VERSION "2027-draft-2026-10-23"

NS_ :

BS_:

BU_: BPS DEI External LVC MIKA MPPTInterface PDU Pedals VCU
VAL_TABLE_ EnableDisable 1 "Enabled" 0 "Disabled" ;
VAL_TABLE_ OnOff 1 "On" 0 "Off" ;
VAL_TABLE_ FaultState 1 "Fault" 0 "OK" ;
VAL_TABLE_ WarningState 1 "Warning" 0 "NoWarning" ;
VAL_TABLE_ DeviceStatus 2 "Waiting" 1 "Fault" 0 "OK" ;
VAL_TABLE_ Permission 1 "Allowed" 0 "NotAllowed" ;
VAL_TABLE_ Connection 1 "Connected" 0 "Disconnected" ;
VAL_TABLE_ BalancingMode 2 "Manual" 1 "Automatic" 0 "Off" ;
VAL_TABLE_ BalancingState 4 "BlockedOrFault" 3 "Complete" 2 "Paused" 1 "Balancing" 0 "Off" ;
VAL_TABLE_ BalancingBlockReason 7 "Other" 6 "BPSFault" 5 "Communication" 4 "VehicleState" 3 "CellVoltage" 2 "ChipTemperature" 1 "CellTemperature" 0 "None" ;
VAL_TABLE_ ServerConnection 1 "Connected" 0 "Disconnected/Retrying" ;
VAL_TABLE_ Pressed 1 "Pressed" 0 "NotPressed" ;
VAL_TABLE_ Validity 1 "Valid" 0 "Invalid" ;
VAL_TABLE_ Watchdog 1 "TimedOut" 0 "Alive" ;
VAL_TABLE_ NormalAdvanced 1 "Advanced" 0 "Normal" ;
VAL_TABLE_ MotorCommandSource 1 "External" 0 "VCU" ;
VAL_TABLE_ Gear 3 "Invalid" 2 "Reverse" 1 "Forward" 0 "Neutral" ;
VAL_TABLE_ BPSFaultSummary 5 "SMBFault" 4 "PrechargeFault" 3 "ContactorRelayFault" 2 "EmergencyStop" 1 "SetpointFault" 0 "OK" ;
VAL_TABLE_ VCUState 7 "VehicleNotReady" 6 "Disabled" 5 "CruiseControl" 4 "Regen" 3 "ReverseDrive" 2 "NeutralDrive" 1 "ForwardDrive" 0 "Init" ;
VAL_TABLE_ ChargeState 2 "Charging" 1 "Standby" 0 "Disabled" ;
VAL_TABLE_ EVSEState 5 "F_EVSEFault" 4 "E_Fault" 3 "D_VentilationRequired" 2 "C_ChargingReady" 1 "B_Connected" 0 "A_Disconnected" ;
VAL_TABLE_ GPSAntennaState 3 "Unknown" 2 "ShortCircuit" 1 "OpenCircuit" 0 "OK" ;
VAL_TABLE_ GPSFix 2 "Fix3D" 1 "Fix2D" 0 "NoFix" ;
VAL_TABLE_ CellularTechnology 4 "Other" 3 "NB_IoT" 2 "LTE_M" 1 "LTE" 0 "None" ;
VAL_TABLE_ TPEEControlMode 2 "ConstantInputVoltage" 1 "PerturbAndObserve" 0 "Disabled" ;
VAL_TABLE_ TPEEOperatingMode 7 "Fault" 6 "MinimumInputVoltage" 5 "TemperatureDerating" 4 "ConstantOutputCurrent" 3 "ConstantOutputVoltage" 2 "MinimumInputCurrent" 1 "ConstantInputCurrent" 0 "ConstantInputVoltage" ;
VAL_TABLE_ TPEEFault 8 "Fault" 7 "PhaseOverCurrent" 6 "InputUnderCurrent" 5 "InputOverCurrent" 4 "OutputOverCurrent" 3 "OutputOverVoltage" 2 "InputOverVoltage" 1 "ConfigurationError" 0 "OK" ;
VAL_TABLE_ LWSCalibration 1 "Calibrated" 0 "NotCalibrated" ;
VAL_TABLE_ LWSTrim 1 "Trimmed" 0 "NotTrimmed" ;
VAL_TABLE_ LWSCommand 5 "ResetCalibration" 3 "SetAngleZero" ;
VAL_TABLE_ ElconControl 1 "Disable" 0 "Charge" ;
VAL_TABLE_ ElconMuxPage 5 "Page5" 4 "Page4" 3 "Page3" 2 "Page2" 1 "Page1" ;

BO_ 81 BPSCommand: 12 External
 SG_ Mode : 0|1@1+ (1,0) [0.0|1.0] "" Vector__XXX
 SG_ MPPTChargeScheme : 1|1@1+ (1,0) [0.0|1.0] "" Vector__XXX
 SG_ VoltageOverrideMask : 2|32@1+ (1,0) [0.0|4294967295.0] "" Vector__XXX
 SG_ TemperatureOverrideMask : 34|32@1+ (1,0) [0.0|4294967295.0] "" Vector__XXX
 SG_ CurrentOverride : 66|1@1+ (1,0) [0.0|1.0] "" Vector__XXX

BO_ 82 PDUCommand: 1 External
 SG_ ChannelIndex : 0|4@1+ (1,0) [0|11] "" Vector__XXX
 SG_ Enable : 4|1@1+ (1,0) [0.0|1.0] "" Vector__XXX

BO_ 83 MotorControllerCommand: 1 External
 SG_ CommandSource : 0|1@1+ (1,0) [0.0|1.0] "" Vector__XXX

BO_ 84 SweepMPPTs: 0 External

BO_ 85 BPSBalancingCommand: 5 External
 SG_ BalancingMode : 0|2@1+ (1,0) [0|2] "" Vector__XXX
 SG_ ManualCellMask : 2|32@1+ (1,0) [0|4294967295] "" Vector__XXX

BO_ 96 BPSStatus: 16 BPS
 SG_ Status : 0|2@1+ (1,0) [0.0|3.0] "" Vector__XXX
 SG_ FaultSummary : 2|3@1+ (1,0) [0.0|7.0] "" Vector__XXX
 SG_ FaultOverTemperature : 5|1@1+ (1,0) [0.0|1.0] "" Vector__XXX
 SG_ FaultOverVoltage : 6|1@1+ (1,0) [0.0|1.0] "" Vector__XXX
 SG_ FaultUnderVoltage : 7|1@1+ (1,0) [0.0|1.0] "" Vector__XXX
 SG_ FaultChargeOverCurrent : 8|1@1+ (1,0) [0.0|1.0] "" Vector__XXX
 SG_ FaultDischargeOverCurrent : 9|1@1+ (1,0) [0.0|1.0] "" Vector__XXX
 SG_ FaultHVPositiveContactorMismatch : 10|1@1+ (1,0) [0.0|1.0] "" Vector__XXX
 SG_ FaultMotorContactorMismatch : 11|1@1+ (1,0) [0.0|1.0] "" Vector__XXX
 SG_ FaultHVNegativeContactorMismatch : 12|1@1+ (1,0) [0.0|1.0] "" Vector__XXX
 SG_ FaultMainPrechargeRelayMismatch : 13|1@1+ (1,0) [0.0|1.0] "" Vector__XXX
 SG_ FaultMotorPrechargeRelayMismatch : 14|1@1+ (1,0) [0.0|1.0] "" Vector__XXX
 SG_ FaultDriverEstop : 15|1@1+ (1,0) [0.0|1.0] "" Vector__XXX
 SG_ FaultExternalEstop : 16|1@1+ (1,0) [0.0|1.0] "" Vector__XXX
 SG_ FaultBatteryEstop : 17|1@1+ (1,0) [0.0|1.0] "" Vector__XXX
 SG_ FaultChargerEstop : 18|1@1+ (1,0) [0.0|1.0] "" Vector__XXX
 SG_ FaultMainPrechargeTimeout : 19|1@1+ (1,0) [0.0|1.0] "" Vector__XXX
 SG_ FaultMotorPrechargeTimeout : 20|1@1+ (1,0) [0.0|1.0] "" Vector__XXX
 SG_ FaultMainVoltage : 21|1@1+ (1,0) [0.0|1.0] "" Vector__XXX
 SG_ FaultMotorVoltage : 22|1@1+ (1,0) [0.0|1.0] "" Vector__XXX
 SG_ FaultMainPrechargeVoltage : 23|1@1+ (1,0) [0.0|1.0] "" Vector__XXX
 SG_ FaultMotorPrechargeVoltage : 24|1@1+ (1,0) [0.0|1.0] "" Vector__XXX
 SG_ WarningSMBCommunication : 25|1@1+ (1,0) [0.0|1.0] "" Vector__XXX
 SG_ WarningUnderVoltage : 26|1@1+ (1,0) [0.0|1.0] "" Vector__XXX
 SG_ WarningOverVoltage : 27|1@1+ (1,0) [0.0|1.0] "" Vector__XXX
 SG_ WarningChargeOverTemperature : 28|1@1+ (1,0) [0.0|1.0] "" Vector__XXX
 SG_ WarningDischargeOverTemperature : 29|1@1+ (1,0) [0.0|1.0] "" Vector__XXX
 SG_ WarningBatteryFan1 : 30|1@1+ (1,0) [0.0|1.0] "" Vector__XXX
 SG_ WarningBatteryFan2 : 31|1@1+ (1,0) [0.0|1.0] "" Vector__XXX
 SG_ WarningBPSFan : 32|1@1+ (1,0) [0.0|1.0] "" Vector__XXX
 SG_ DischargeSafe : 33|1@1+ (1,0) [0.0|1.0] "" Vector__XXX
 SG_ ChargeSafe : 34|1@1+ (1,0) [0.0|1.0] "" Vector__XXX
 SG_ MPPTSetMode : 35|2@1+ (1,0) [0.0|3.0] "" Vector__XXX
 SG_ RegenSafe : 37|1@1+ (1,0) [0.0|1.0] "" Vector__XXX
 SG_ HVPositiveContactor : 38|1@1+ (1,0) [0.0|1.0] "" Vector__XXX
 SG_ MotorContactor : 39|1@1+ (1,0) [0.0|1.0] "" Vector__XXX
 SG_ HVNegativeContactor : 40|1@1+ (1,0) [0.0|1.0] "" Vector__XXX
 SG_ MainPrechargeRelay : 41|1@1+ (1,0) [0.0|1.0] "" Vector__XXX
 SG_ MotorPrechargeRelay : 42|1@1+ (1,0) [0.0|1.0] "" Vector__XXX
 SG_ BalancingActive : 43|1@1+ (1,0) [0.0|1.0] "" Vector__XXX
 SG_ MPPTVoltageLimit : 44|16@1+ (0.05,0) [0|175] "V" Vector__XXX
 SG_ MPPTCurrentLimit : 60|16@1+ (0.01,0) [0|16.38] "A" Vector__XXX
 SG_ BatteryFanTach1 : 76|12@1+ (5,0) [0.0|20475.0] "rpm" Vector__XXX
 SG_ BatteryFanTach2 : 88|12@1+ (5,0) [0.0|20475.0] "rpm" Vector__XXX
 SG_ BPSFanTach : 100|12@1+ (5,0) [0.0|20475.0] "rpm" Vector__XXX

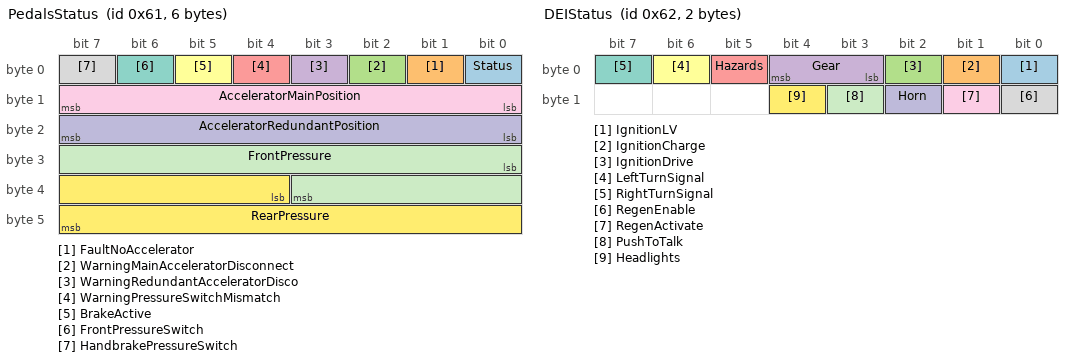
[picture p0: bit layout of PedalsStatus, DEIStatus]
BO_ 97 PedalsStatus: 6 Pedals
 SG_ Status : 0|1@1+ (1,0) [0.0|1.0] "" Vector__XXX
 SG_ FaultNoAccelerator : 1|1@1+ (1,0) [0.0|1.0] "" Vector__XXX
 SG_ WarningMainAcceleratorDisconnect : 2|1@1+ (1,0) [0.0|1.0] "" Vector__XXX
 SG_ WarningRedundantAcceleratorDisco : 3|1@1+ (1,0) [0.0|1.0] "" Vector__XXX
 SG_ WarningPressureSwitchMismatch : 4|1@1+ (1,0) [0.0|1.0] "" Vector__XXX
 SG_ BrakeActive : 5|1@1+ (1,0) [0.0|1.0] "" Vector__XXX
 SG_ FrontPressureSwitch : 6|1@1+ (1,0) [0.0|1.0] "" Vector__XXX
 SG_ HandbrakePressureSwitch : 7|1@1+ (1,0) [0.0|1.0] "" Vector__XXX
 SG_ AcceleratorMainPosition : 8|8@1+ (0.39215686274509803,0) [0|100] "%" Vector__XXX
 SG_ AcceleratorRedundantPosition : 16|8@1+ (0.39215686274509803,0) [0|100] "%" Vector__XXX
 SG_ FrontPressure : 24|12@1+ (1,0) [0|3000] "PSI" Vector__XXX
 SG_ RearPressure : 36|12@1+ (1,0) [0|3000] "PSI" Vector__XXX

BO_ 98 DEIStatus: 2 DEI
 SG_ IgnitionLV : 0|1@1+ (1,0) [0.0|1.0] "" Vector__XXX
 SG_ IgnitionCharge : 1|1@1+ (1,0) [0.0|1.0] "" Vector__XXX
 SG_ IgnitionDrive : 2|1@1+ (1,0) [0.0|1.0] "" Vector__XXX
 SG_ Gear : 3|2@1+ (1,0) [0.0|3.0] "" Vector__XXX
 SG_ Hazards : 5|1@1+ (1,0) [0.0|1.0] "" Vector__XXX
 SG_ LeftTurnSignal : 6|1@1+ (1,0) [0.0|1.0] "" Vector__XXX
 SG_ RightTurnSignal : 7|1@1+ (1,0) [0.0|1.0] "" Vector__XXX
 SG_ RegenEnable : 8|1@1+ (1,0) [0.0|1.0] "" Vector__XXX
 SG_ RegenActivate : 9|1@1+ (1,0) [0.0|1.0] "" Vector__XXX
 SG_ Horn : 10|1@1+ (1,0) [0.0|1.0] "" Vector__XXX
 SG_ PushToTalk : 11|1@1+ (1,0) [0.0|1.0] "" Vector__XXX
 SG_ Headlights : 12|1@1+ (1,0) [0.0|1.0] "" Vector__XXX

BO_ 99 VCUStatus: 6 VCU
 SG_ Status : 0|1@1+ (1,0) [0.0|1.0] "" Vector__XXX
 SG_ FaultMotor : 1|1@1+ (1,0) [0.0|1.0] "" Vector__XXX
 SG_ FaultBPS : 2|1@1+ (1,0) [0.0|1.0] "" Vector__XXX
 SG_ FaultPedals : 3|1@1+ (1,0) [0.0|1.0] "" Vector__XXX
 SG_ FaultMotorControllerWatchdog : 4|1@1+ (1,0) [0.0|1.0] "" Vector__XXX
 SG_ FaultBPSWatchdog : 5|1@1+ (1,0) [0.0|1.0] "" Vector__XXX
 SG_ FaultDriverInputWatchdog : 6|1@1+ (1,0) [0.0|1.0] "" Vector__XXX
 SG_ FaultPedalsWatchdog : 7|1@1+ (1,0) [0.0|1.0] "" Vector__XXX
 SG_ WarningTipping : 8|1@1+ (1,0) [0.0|1.0] "" Vector__XXX
 SG_ WarningDirectionChangeLockout : 9|1@1+ (1,0) [0.0|1.0] "" Vector__XXX
 SG_ WarningMotorControllerFan : 10|1@1+ (1,0) [0.0|1.0] "" Vector__XXX
 SG_ WarningMotorFan : 11|1@1+ (1,0) [0.0|1.0] "" Vector__XXX
 SG_ RegenEnabled : 12|1@1+ (1,0) [0.0|1.0] "" Vector__XXX
 SG_ State : 13|3@1+ (1,0) [0.0|7.0] "" Vector__XXX
 SG_ FSMBrake : 16|1@1+ (1,0) [0.0|1.0] "" Vector__XXX
 SG_ FSMBPSDriveOK : 17|1@1+ (1,0) [0.0|1.0] "" Vector__XXX
 SG_ FSMBPSRegenOK : 18|1@1+ (1,0) [0.0|1.0] "" Vector__XXX
 SG_ FSMDriverRegenEnable : 19|1@1+ (1,0) [0.0|1.0] "" Vector__XXX
 SG_ FSMDriverRegenRequest : 20|1@1+ (1,0) [0.0|1.0] "" Vector__XXX
 SG_ FSMGear : 21|2@1+ (1,0) [0.0|3.0] "" Vector__XXX
 SG_ MotorCommandSource : 23|1@1+ (1,0) [0.0|1.0] "" Vector__XXX
 SG_ MotorControllerFanTach : 24|12@1+ (5,0) [0.0|20475.0] "rpm" Vector__XXX
 SG_ MotorFanTach : 36|12@1+ (5,0) [0.0|20475.0] "rpm" Vector__XXX

BO_ 112 BPSPackData: 12 BPS
 SG_ CellSumVoltage : 0|12@1+ (0.05,0) [0.0|204.75] "V" Vector__XXX
 SG_ MainBatteryVoltage : 12|12@1+ (0.05,0) [0.0|204.75] "V" Vector__XXX
 SG_ MotorBatteryVoltage : 24|12@1+ (0.05,0) [0.0|204.75] "V" Vector__XXX
 SG_ MainVoltage : 36|12@1+ (0.05,0) [0.0|204.75] "V" Vector__XXX
 SG_ MotorVoltage : 48|12@1+ (0.05,0) [0.0|204.75] "V" Vector__XXX
 SG_ BatteryCurrent : 60|14@1+ (0.01,-50) [-50.0|113.83] "A" Vector__XXX

BO_ 113 BPSVoltageData: 64 BPS
 SG_ MinCellVoltageIndex : 0|5@1+ (1,0) [0|31] "" Vector__XXX
 SG_ MaxCellVoltageIndex : 5|5@1+ (1,0) [0|31] "" Vector__XXX
 SG_ CellVoltage00 : 10|12@1+ (1,2000) [2000.0|6095.0] "mV" Vector__XXX
 SG_ CellVoltage01 : 22|12@1+ (1,2000) [2000.0|6095.0] "mV" Vector__XXX
 SG_ CellVoltage02 : 34|12@1+ (1,2000) [2000.0|6095.0] "mV" Vector__XXX
 SG_ CellVoltage03 : 46|12@1+ (1,2000) [2000.0|6095.0] "mV" Vector__XXX
 SG_ CellVoltage04 : 58|12@1+ (1,2000) [2000.0|6095.0] "mV" Vector__XXX
 SG_ CellVoltage05 : 70|12@1+ (1,2000) [2000.0|6095.0] "mV" Vector__XXX
 SG_ CellVoltage06 : 82|12@1+ (1,2000) [2000.0|6095.0] "mV" Vector__XXX
 SG_ CellVoltage07 : 94|12@1+ (1,2000) [2000.0|6095.0] "mV" Vector__XXX
 SG_ CellVoltage08 : 106|12@1+ (1,2000) [2000.0|6095.0] "mV" Vector__XXX
 SG_ CellVoltage09 : 118|12@1+ (1,2000) [2000.0|6095.0] "mV" Vector__XXX
 SG_ CellVoltage10 : 130|12@1+ (1,2000) [2000.0|6095.0] "mV" Vector__XXX
 SG_ CellVoltage11 : 142|12@1+ (1,2000) [2000.0|6095.0] "mV" Vector__XXX
 SG_ CellVoltage12 : 154|12@1+ (1,2000) [2000.0|6095.0] "mV" Vector__XXX
 SG_ CellVoltage13 : 166|12@1+ (1,2000) [2000.0|6095.0] "mV" Vector__XXX
 SG_ CellVoltage14 : 178|12@1+ (1,2000) [2000.0|6095.0] "mV" Vector__XXX
 SG_ CellVoltage15 : 190|12@1+ (1,2000) [2000.0|6095.0] "mV" Vector__XXX
 SG_ CellVoltage16 : 202|12@1+ (1,2000) [2000.0|6095.0] "mV" Vector__XXX
 SG_ CellVoltage17 : 214|12@1+ (1,2000) [2000.0|6095.0] "mV" Vector__XXX
 SG_ CellVoltage18 : 226|12@1+ (1,2000) [2000.0|6095.0] "mV" Vector__XXX
 SG_ CellVoltage19 : 238|12@1+ (1,2000) [2000.0|6095.0] "mV" Vector__XXX
 SG_ CellVoltage20 : 250|12@1+ (1,2000) [2000.0|6095.0] "mV" Vector__XXX
 SG_ CellVoltage21 : 262|12@1+ (1,2000) [2000.0|6095.0] "mV" Vector__XXX
 SG_ CellVoltage22 : 274|12@1+ (1,2000) [2000.0|6095.0] "mV" Vector__XXX
 SG_ CellVoltage23 : 286|12@1+ (1,2000) [2000.0|6095.0] "mV" Vector__XXX
 SG_ CellVoltage24 : 298|12@1+ (1,2000) [2000.0|6095.0] "mV" Vector__XXX
 SG_ CellVoltage25 : 310|12@1+ (1,2000) [2000.0|6095.0] "mV" Vector__XXX
 SG_ CellVoltage26 : 322|12@1+ (1,2000) [2000.0|6095.0] "mV" Vector__XXX
 SG_ CellVoltage27 : 334|12@1+ (1,2000) [2000.0|6095.0] "mV" Vector__XXX
 SG_ CellVoltage28 : 346|12@1+ (1,2000) [2000.0|6095.0] "mV" Vector__XXX
 SG_ CellVoltage29 : 358|12@1+ (1,2000) [2000.0|6095.0] "mV" Vector__XXX
 SG_ CellVoltage30 : 370|12@1+ (1,2000) [2000.0|6095.0] "mV" Vector__XXX
 SG_ CellVoltage31 : 382|12@1+ (1,2000) [2000.0|6095.0] "mV" Vector__XXX
 SG_ MinCellVoltage : 394|12@1+ (1,2000) [2000.0|6095.0] "mV" Vector__XXX
 SG_ MaxCellVoltage : 406|12@1+ (1,2000) [2000.0|6095.0] "mV" Vector__XXX

BO_ 114 BPSTemperatureData: 48 BPS
 SG_ MaxBatteryTemperatureIndex : 0|5@1+ (1,0) [0|31] "" Vector__XXX
 SG_ CellTemperature00 : 5|11@1+ (0.05,0) [0.0|102.35] "degC" Vector__XXX
 SG_ CellTemperature01 : 16|11@1+ (0.05,0) [0.0|102.35] "degC" Vector__XXX
 SG_ CellTemperature02 : 27|11@1+ (0.05,0) [0.0|102.35] "degC" Vector__XXX
 SG_ CellTemperature03 : 38|11@1+ (0.05,0) [0.0|102.35] "degC" Vector__XXX
 SG_ CellTemperature04 : 49|11@1+ (0.05,0) [0.0|102.35] "degC" Vector__XXX
 SG_ CellTemperature05 : 60|11@1+ (0.05,0) [0.0|102.35] "degC" Vector__XXX
 SG_ CellTemperature06 : 71|11@1+ (0.05,0) [0.0|102.35] "degC" Vector__XXX
 SG_ CellTemperature07 : 82|11@1+ (0.05,0) [0.0|102.35] "degC" Vector__XXX
 SG_ CellTemperature08 : 93|11@1+ (0.05,0) [0.0|102.35] "degC" Vector__XXX
 SG_ CellTemperature09 : 104|11@1+ (0.05,0) [0.0|102.35] "degC" Vector__XXX
 SG_ CellTemperature10 : 115|11@1+ (0.05,0) [0.0|102.35] "degC" Vector__XXX
 SG_ CellTemperature11 : 126|11@1+ (0.05,0) [0.0|102.35] "degC" Vector__XXX
 SG_ CellTemperature12 : 137|11@1+ (0.05,0) [0.0|102.35] "degC" Vector__XXX
 SG_ CellTemperature13 : 148|11@1+ (0.05,0) [0.0|102.35] "degC" Vector__XXX
 SG_ CellTemperature14 : 159|11@1+ (0.05,0) [0.0|102.35] "degC" Vector__XXX
 SG_ CellTemperature15 : 170|11@1+ (0.05,0) [0.0|102.35] "degC" Vector__XXX
 SG_ CellTemperature16 : 181|11@1+ (0.05,0) [0.0|102.35] "degC" Vector__XXX
 SG_ CellTemperature17 : 192|11@1+ (0.05,0) [0.0|102.35] "degC" Vector__XXX
 SG_ CellTemperature18 : 203|11@1+ (0.05,0) [0.0|102.35] "degC" Vector__XXX
 SG_ CellTemperature19 : 214|11@1+ (0.05,0) [0.0|102.35] "degC" Vector__XXX
 SG_ CellTemperature20 : 225|11@1+ (0.05,0) [0.0|102.35] "degC" Vector__XXX
 SG_ CellTemperature21 : 236|11@1+ (0.05,0) [0.0|102.35] "degC" Vector__XXX
 SG_ CellTemperature22 : 247|11@1+ (0.05,0) [0.0|102.35] "degC" Vector__XXX
 SG_ CellTemperature23 : 258|11@1+ (0.05,0) [0.0|102.35] "degC" Vector__XXX
 SG_ CellTemperature24 : 269|11@1+ (0.05,0) [0.0|102.35] "degC" Vector__XXX
 SG_ CellTemperature25 : 280|11@1+ (0.05,0) [0.0|102.35] "degC" Vector__XXX
 SG_ CellTemperature26 : 291|11@1+ (0.05,0) [0.0|102.35] "degC" Vector__XXX
 SG_ CellTemperature27 : 302|11@1+ (0.05,0) [0.0|102.35] "degC" Vector__XXX
 SG_ CellTemperature28 : 313|11@1+ (0.05,0) [0.0|102.35] "degC" Vector__XXX
 SG_ CellTemperature29 : 324|11@1+ (0.05,0) [0.0|102.35] "degC" Vector__XXX
 SG_ CellTemperature30 : 335|11@1+ (0.05,0) [0.0|102.35] "degC" Vector__XXX
 SG_ CellTemperature31 : 346|11@1+ (0.05,0) [0.0|102.35] "degC" Vector__XXX
 SG_ MaxBatteryTemperature : 357|11@1+ (0.05,0) [0.0|102.35] "degC" Vector__XXX
 SG_ AverageBatteryTemperature : 368|11@1+ (0.05,0) [0.0|102.35] "degC" Vector__XXX

BO_ 115 SMDStatus: 0 BPS

BO_ 116 BPSCommandEcho: 12 BPS
 SG_ Mode : 0|1@1+ (1,0) [0.0|1.0] "" Vector__XXX
 SG_ MPPTChargeScheme : 1|1@1+ (1,0) [0.0|1.0] "" Vector__XXX
 SG_ VoltageOverrideMask : 2|32@1+ (1,0) [0.0|4294967295.0] "" Vector__XXX
 SG_ TemperatureOverrideMask : 34|32@1+ (1,0) [0.0|4294967295.0] "" Vector__XXX
 SG_ CurrentOverride : 66|1@1+ (1,0) [0.0|1.0] "" Vector__XXX

BO_ 117 BPSFaultSnapshot: 12 BPS
 SG_ FaultSummary : 0|3@1+ (1,0) [0.0|7.0] "" Vector__XXX
 SG_ FaultOverTemperature : 3|1@1+ (1,0) [0.0|1.0] "" Vector__XXX
 SG_ FaultOverVoltage : 4|1@1+ (1,0) [0.0|1.0] "" Vector__XXX
 SG_ FaultUnderVoltage : 5|1@1+ (1,0) [0.0|1.0] "" Vector__XXX
 SG_ FaultChargeOverCurrent : 6|1@1+ (1,0) [0.0|1.0] "" Vector__XXX
 SG_ FaultDischargeOverCurrent : 7|1@1+ (1,0) [0.0|1.0] "" Vector__XXX
 SG_ FaultHVPositiveContactorMismatch : 8|1@1+ (1,0) [0.0|1.0] "" Vector__XXX
 SG_ FaultMotorContactorMismatch : 9|1@1+ (1,0) [0.0|1.0] "" Vector__XXX
 SG_ FaultHVNegativeContactorMismatch : 10|1@1+ (1,0) [0.0|1.0] "" Vector__XXX
 SG_ FaultMainPrechargeRelayMismatch : 11|1@1+ (1,0) [0.0|1.0] "" Vector__XXX
 SG_ FaultMotorPrechargeRelayMismatch : 12|1@1+ (1,0) [0.0|1.0] "" Vector__XXX
 SG_ FaultDriverEstop : 13|1@1+ (1,0) [0.0|1.0] "" Vector__XXX
 SG_ FaultExternalEstop : 14|1@1+ (1,0) [0.0|1.0] "" Vector__XXX
 SG_ FaultBatteryEstop : 15|1@1+ (1,0) [0.0|1.0] "" Vector__XXX
 SG_ FaultChargerEstop : 16|1@1+ (1,0) [0.0|1.0] "" Vector__XXX
 SG_ FaultMainPrechargeTimeout : 17|1@1+ (1,0) [0.0|1.0] "" Vector__XXX
 SG_ FaultMotorPrechargeTimeout : 18|1@1+ (1,0) [0.0|1.0] "" Vector__XXX
 SG_ FaultMainVoltage : 19|1@1+ (1,0) [0.0|1.0] "" Vector__XXX
 SG_ FaultMotorVoltage : 20|1@1+ (1,0) [0.0|1.0] "" Vector__XXX
 SG_ FaultMainPrechargeVoltage : 21|1@1+ (1,0) [0.0|1.0] "" Vector__XXX
 SG_ FaultMotorPrechargeVoltage : 22|1@1+ (1,0) [0.0|1.0] "" Vector__XXX
 SG_ CurrentValid : 23|1@1+ (1,0) [0|1] "" Vector__XXX
 SG_ CaptureTimeMs : 24|32@1+ (1,0) [0|4294967295] "ms" Vector__XXX
 SG_ BatteryCurrent : 56|14@1+ (0.01,-50) [-50.0|113.83] "A" Vector__XXX

BO_ 118 BPSFaultVoltageSnapshot: 64 BPS
 SG_ SampleValidMask : 0|32@1+ (1,0) [0|4294967295] "" Vector__XXX
 SG_ CellVoltage00 : 32|12@1+ (1,2000) [2000.0|6095.0] "mV" Vector__XXX
 SG_ CellVoltage01 : 44|12@1+ (1,2000) [2000.0|6095.0] "mV" Vector__XXX
 SG_ CellVoltage02 : 56|12@1+ (1,2000) [2000.0|6095.0] "mV" Vector__XXX
 SG_ CellVoltage03 : 68|12@1+ (1,2000) [2000.0|6095.0] "mV" Vector__XXX
 SG_ CellVoltage04 : 80|12@1+ (1,2000) [2000.0|6095.0] "mV" Vector__XXX
 SG_ CellVoltage05 : 92|12@1+ (1,2000) [2000.0|6095.0] "mV" Vector__XXX
 SG_ CellVoltage06 : 104|12@1+ (1,2000) [2000.0|6095.0] "mV" Vector__XXX
 SG_ CellVoltage07 : 116|12@1+ (1,2000) [2000.0|6095.0] "mV" Vector__XXX
 SG_ CellVoltage08 : 128|12@1+ (1,2000) [2000.0|6095.0] "mV" Vector__XXX
 SG_ CellVoltage09 : 140|12@1+ (1,2000) [2000.0|6095.0] "mV" Vector__XXX
 SG_ CellVoltage10 : 152|12@1+ (1,2000) [2000.0|6095.0] "mV" Vector__XXX
 SG_ CellVoltage11 : 164|12@1+ (1,2000) [2000.0|6095.0] "mV" Vector__XXX
 SG_ CellVoltage12 : 176|12@1+ (1,2000) [2000.0|6095.0] "mV" Vector__XXX
 SG_ CellVoltage13 : 188|12@1+ (1,2000) [2000.0|6095.0] "mV" Vector__XXX
 SG_ CellVoltage14 : 200|12@1+ (1,2000) [2000.0|6095.0] "mV" Vector__XXX
 SG_ CellVoltage15 : 212|12@1+ (1,2000) [2000.0|6095.0] "mV" Vector__XXX
 SG_ CellVoltage16 : 224|12@1+ (1,2000) [2000.0|6095.0] "mV" Vector__XXX
 SG_ CellVoltage17 : 236|12@1+ (1,2000) [2000.0|6095.0] "mV" Vector__XXX
 SG_ CellVoltage18 : 248|12@1+ (1,2000) [2000.0|6095.0] "mV" Vector__XXX
 SG_ CellVoltage19 : 260|12@1+ (1,2000) [2000.0|6095.0] "mV" Vector__XXX
 SG_ CellVoltage20 : 272|12@1+ (1,2000) [2000.0|6095.0] "mV" Vector__XXX
 SG_ CellVoltage21 : 284|12@1+ (1,2000) [2000.0|6095.0] "mV" Vector__XXX
 SG_ CellVoltage22 : 296|12@1+ (1,2000) [2000.0|6095.0] "mV" Vector__XXX
 SG_ CellVoltage23 : 308|12@1+ (1,2000) [2000.0|6095.0] "mV" Vector__XXX
 SG_ CellVoltage24 : 320|12@1+ (1,2000) [2000.0|6095.0] "mV" Vector__XXX
 SG_ CellVoltage25 : 332|12@1+ (1,2000) [2000.0|6095.0] "mV" Vector__XXX
 SG_ CellVoltage26 : 344|12@1+ (1,2000) [2000.0|6095.0] "mV" Vector__XXX
 SG_ CellVoltage27 : 356|12@1+ (1,2000) [2000.0|6095.0] "mV" Vector__XXX
 SG_ CellVoltage28 : 368|12@1+ (1,2000) [2000.0|6095.0] "mV" Vector__XXX
 SG_ CellVoltage29 : 380|12@1+ (1,2000) [2000.0|6095.0] "mV" Vector__XXX
 SG_ CellVoltage30 : 392|12@1+ (1,2000) [2000.0|6095.0] "mV" Vector__XXX
 SG_ CellVoltage31 : 404|12@1+ (1,2000) [2000.0|6095.0] "mV" Vector__XXX

BO_ 119 BPSFaultTemperatureSnapshot: 48 BPS
 SG_ SampleValidMask : 0|32@1+ (1,0) [0|4294967295] "" Vector__XXX
 SG_ CellTemperature00 : 32|11@1+ (0.05,0) [0.0|102.35] "degC" Vector__XXX
 SG_ CellTemperature01 : 43|11@1+ (0.05,0) [0.0|102.35] "degC" Vector__XXX
 SG_ CellTemperature02 : 54|11@1+ (0.05,0) [0.0|102.35] "degC" Vector__XXX
 SG_ CellTemperature03 : 65|11@1+ (0.05,0) [0.0|102.35] "degC" Vector__XXX
 SG_ CellTemperature04 : 76|11@1+ (0.05,0) [0.0|102.35] "degC" Vector__XXX
 SG_ CellTemperature05 : 87|11@1+ (0.05,0) [0.0|102.35] "degC" Vector__XXX
 SG_ CellTemperature06 : 98|11@1+ (0.05,0) [0.0|102.35] "degC" Vector__XXX
 SG_ CellTemperature07 : 109|11@1+ (0.05,0) [0.0|102.35] "degC" Vector__XXX
 SG_ CellTemperature08 : 120|11@1+ (0.05,0) [0.0|102.35] "degC" Vector__XXX
 SG_ CellTemperature09 : 131|11@1+ (0.05,0) [0.0|102.35] "degC" Vector__XXX
 SG_ CellTemperature10 : 142|11@1+ (0.05,0) [0.0|102.35] "degC" Vector__XXX
 SG_ CellTemperature11 : 153|11@1+ (0.05,0) [0.0|102.35] "degC" Vector__XXX
 SG_ CellTemperature12 : 164|11@1+ (0.05,0) [0.0|102.35] "degC" Vector__XXX
 SG_ CellTemperature13 : 175|11@1+ (0.05,0) [0.0|102.35] "degC" Vector__XXX
 SG_ CellTemperature14 : 186|11@1+ (0.05,0) [0.0|102.35] "degC" Vector__XXX
 SG_ CellTemperature15 : 197|11@1+ (0.05,0) [0.0|102.35] "degC" Vector__XXX
 SG_ CellTemperature16 : 208|11@1+ (0.05,0) [0.0|102.35] "degC" Vector__XXX
 SG_ CellTemperature17 : 219|11@1+ (0.05,0) [0.0|102.35] "degC" Vector__XXX
 SG_ CellTemperature18 : 230|11@1+ (0.05,0) [0.0|102.35] "degC" Vector__XXX
 SG_ CellTemperature19 : 241|11@1+ (0.05,0) [0.0|102.35] "degC" Vector__XXX
 SG_ CellTemperature20 : 252|11@1+ (0.05,0) [0.0|102.35] "degC" Vector__XXX
 SG_ CellTemperature21 : 263|11@1+ (0.05,0) [0.0|102.35] "degC" Vector__XXX
 SG_ CellTemperature22 : 274|11@1+ (0.05,0) [0.0|102.35] "degC" Vector__XXX
 SG_ CellTemperature23 : 285|11@1+ (0.05,0) [0.0|102.35] "degC" Vector__XXX
 SG_ CellTemperature24 : 296|11@1+ (0.05,0) [0.0|102.35] "degC" Vector__XXX
 SG_ CellTemperature25 : 307|11@1+ (0.05,0) [0.0|102.35] "degC" Vector__XXX
 SG_ CellTemperature26 : 318|11@1+ (0.05,0) [0.0|102.35] "degC" Vector__XXX
 SG_ CellTemperature27 : 329|11@1+ (0.05,0) [0.0|102.35] "degC" Vector__XXX
 SG_ CellTemperature28 : 340|11@1+ (0.05,0) [0.0|102.35] "degC" Vector__XXX
 SG_ CellTemperature29 : 351|11@1+ (0.05,0) [0.0|102.35] "degC" Vector__XXX
 SG_ CellTemperature30 : 362|11@1+ (0.05,0) [0.0|102.35] "degC" Vector__XXX
 SG_ CellTemperature31 : 373|11@1+ (0.05,0) [0.0|102.35] "degC" Vector__XXX

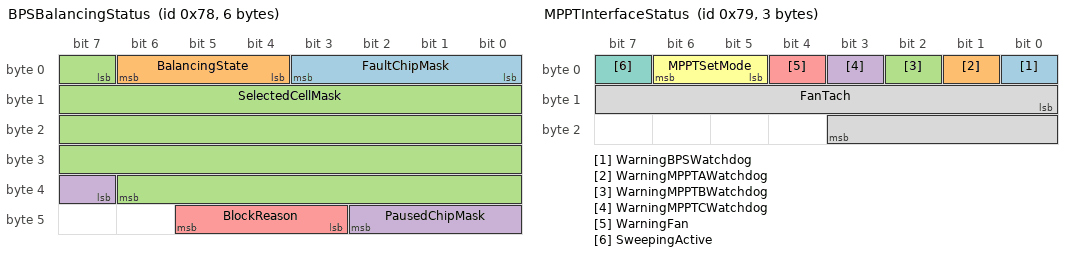
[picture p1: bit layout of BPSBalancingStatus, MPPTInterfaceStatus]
BO_ 120 BPSBalancingStatus: 6 BPS
 SG_ FaultChipMask : 0|4@1+ (1,0) [0|15] "" Vector__XXX
 SG_ BalancingState : 4|3@1+ (1,0) [0|4] "" Vector__XXX
 SG_ SelectedCellMask : 7|32@1+ (1,0) [0|4294967295] "" Vector__XXX
 SG_ PausedChipMask : 39|4@1+ (1,0) [0|15] "" Vector__XXX
 SG_ BlockReason : 43|3@1+ (1,0) [0|7] "" Vector__XXX

BO_ 121 MPPTInterfaceStatus: 3 MPPTInterface
 SG_ WarningBPSWatchdog : 0|1@1+ (1,0) [0.0|1.0] "" Vector__XXX
 SG_ WarningMPPTAWatchdog : 1|1@1+ (1,0) [0.0|1.0] "" Vector__XXX
 SG_ WarningMPPTBWatchdog : 2|1@1+ (1,0) [0.0|1.0] "" Vector__XXX
 SG_ WarningMPPTCWatchdog : 3|1@1+ (1,0) [0.0|1.0] "" Vector__XXX
 SG_ WarningFan : 4|1@1+ (1,0) [0.0|1.0] "" Vector__XXX
 SG_ MPPTSetMode : 5|2@1+ (1,0) [0.0|3.0] "" Vector__XXX
 SG_ SweepingActive : 7|1@1+ (1,0) [0.0|1.0] "" Vector__XXX
 SG_ FanTach : 8|12@1+ (5,0) [0.0|20475.0] "rpm" Vector__XXX

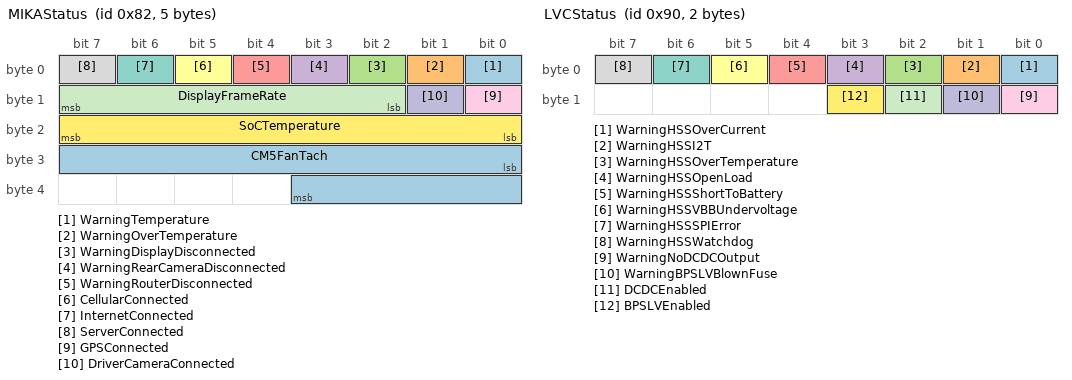
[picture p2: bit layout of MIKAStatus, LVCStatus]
BO_ 130 MIKAStatus: 5 MIKA
 SG_ WarningTemperature : 0|1@1+ (1,0) [0.0|1.0] "" Vector__XXX
 SG_ WarningOverTemperature : 1|1@1+ (1,0) [0.0|1.0] "" Vector__XXX
 SG_ WarningDisplayDisconnected : 2|1@1+ (1,0) [0.0|1.0] "" Vector__XXX
 SG_ WarningRearCameraDisconnected : 3|1@1+ (1,0) [0.0|1.0] "" Vector__XXX
 SG_ WarningRouterDisconnected : 4|1@1+ (1,0) [0.0|1.0] "" Vector__XXX
 SG_ CellularConnected : 5|1@1+ (1,0) [0.0|1.0] "" Vector__XXX
 SG_ InternetConnected : 6|1@1+ (1,0) [0.0|1.0] "" Vector__XXX
 SG_ ServerConnected : 7|1@1+ (1,0) [0|1] "" Vector__XXX
 SG_ GPSConnected : 8|1@1+ (1,0) [0.0|1.0] "" Vector__XXX
 SG_ DriverCameraConnected : 9|1@1+ (1,0) [0.0|1.0] "" Vector__XXX
 SG_ DisplayFrameRate : 10|6@1+ (1,0) [0|60] "FPS" Vector__XXX
 SG_ SoCTemperature : 16|8@1+ (0.5,-20) [-20|85] "degC" Vector__XXX
 SG_ CM5FanTach : 24|12@1+ (5,0) [0|20475] "rpm" Vector__XXX

BO_ 144 LVCStatus: 2 LVC
 SG_ WarningHSSOverCurrent : 0|1@1+ (1,0) [0.0|1.0] "" Vector__XXX
 SG_ WarningHSSI2T : 1|1@1+ (1,0) [0.0|1.0] "" Vector__XXX
 SG_ WarningHSSOverTemperature : 2|1@1+ (1,0) [0.0|1.0] "" Vector__XXX
 SG_ WarningHSSOpenLoad : 3|1@1+ (1,0) [0.0|1.0] "" Vector__XXX
 SG_ WarningHSSShortToBattery : 4|1@1+ (1,0) [0.0|1.0] "" Vector__XXX
 SG_ WarningHSSVBBUndervoltage : 5|1@1+ (1,0) [0.0|1.0] "" Vector__XXX
 SG_ WarningHSSSPIError : 6|1@1+ (1,0) [0.0|1.0] "" Vector__XXX
 SG_ WarningHSSWatchdog : 7|1@1+ (1,0) [0.0|1.0] "" Vector__XXX
 SG_ WarningNoDCDCOutput : 8|1@1+ (1,0) [0.0|1.0] "" Vector__XXX
 SG_ WarningBPSLVBlownFuse : 9|1@1+ (1,0) [0.0|1.0] "" Vector__XXX
 SG_ DCDCEnabled : 10|1@1+ (1,0) [0.0|1.0] "" Vector__XXX
 SG_ BPSLVEnabled : 11|1@1+ (1,0) [0.0|1.0] "" Vector__XXX

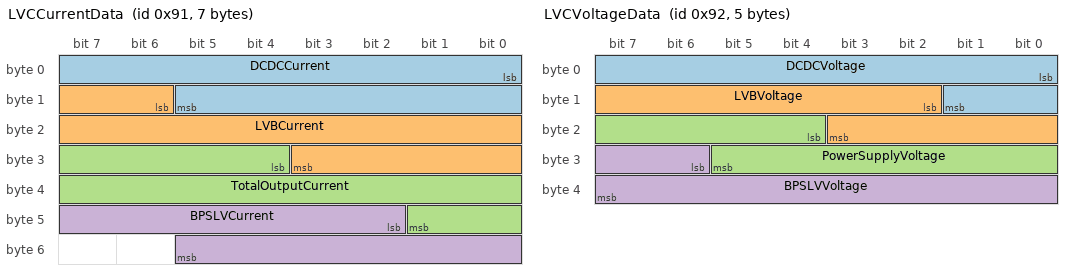
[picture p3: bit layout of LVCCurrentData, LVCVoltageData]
BO_ 145 LVCCurrentData: 7 LVC
 SG_ DCDCCurrent : 0|14@1+ (0.01,0) [0|163.83] "A" Vector__XXX
 SG_ LVBCurrent : 14|14@1+ (0.01,-50) [-50|113.83000000000001] "A" Vector__XXX
 SG_ TotalOutputCurrent : 28|14@1+ (0.01,0) [0|163.83] "A" Vector__XXX
 SG_ BPSLVCurrent : 42|12@1+ (0.01,0) [0|40.95] "A" Vector__XXX

BO_ 146 LVCVoltageData: 5 LVC
 SG_ DCDCVoltage : 0|10@1+ (0.05,0) [0|51.150000000000006] "V" Vector__XXX
 SG_ LVBVoltage : 10|10@1+ (0.05,0) [0|51.150000000000006] "V" Vector__XXX
 SG_ PowerSupplyVoltage : 20|10@1+ (0.05,0) [0|51.150000000000006] "V" Vector__XXX
 SG_ BPSLVVoltage : 30|10@1+ (0.05,0) [0|51.150000000000006] "V" Vector__XXX

BO_ 147 LVCTemperatureData: 2 LVC
 SG_ BPSFETTemperature : 0|13@1+ (0.05,-40) [-40|200] "degC" Vector__XXX

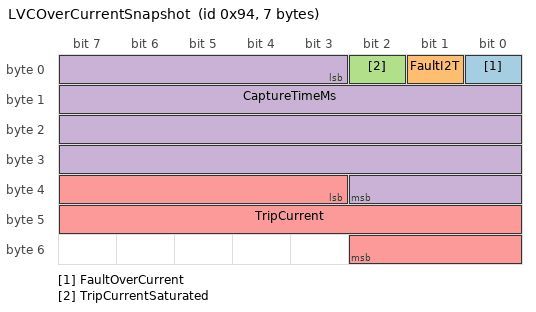
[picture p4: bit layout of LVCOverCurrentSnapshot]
BO_ 148 LVCOverCurrentSnapshot: 7 LVC
 SG_ FaultOverCurrent : 0|1@1+ (1,0) [0.0|1.0] "" Vector__XXX
 SG_ FaultI2T : 1|1@1+ (1,0) [0.0|1.0] "" Vector__XXX
 SG_ TripCurrentSaturated : 2|1@1+ (1,0) [0.0|1.0] "" Vector__XXX
 SG_ CaptureTimeMs : 3|32@1+ (1,0) [0|4294967295] "ms" Vector__XXX
 SG_ TripCurrent : 35|16@1+ (0.01,0) [0|655.35] "A" Vector__XXX

BO_ 160 PDUStatus: 16 PDU
 SG_ FaultChannelOverCurrent0 : 0|1@1+ (1,0) [0.0|1.0] "" Vector__XXX
 SG_ FaultChannelI2T0 : 1|1@1+ (1,0) [0.0|1.0] "" Vector__XXX
 SG_ FaultChannelOverTemperature0 : 2|1@1+ (1,0) [0.0|1.0] "" Vector__XXX
 SG_ FaultChannelOpenLoad0 : 3|1@1+ (1,0) [0.0|1.0] "" Vector__XXX
 SG_ FaultChannelShortToBattery0 : 4|1@1+ (1,0) [0.0|1.0] "" Vector__XXX
 SG_ FaultChannelOverCurrent1 : 5|1@1+ (1,0) [0.0|1.0] "" Vector__XXX
 SG_ FaultChannelI2T1 : 6|1@1+ (1,0) [0.0|1.0] "" Vector__XXX
 SG_ FaultChannelOverTemperature1 : 7|1@1+ (1,0) [0.0|1.0] "" Vector__XXX
 SG_ FaultChannelOpenLoad1 : 8|1@1+ (1,0) [0.0|1.0] "" Vector__XXX
 SG_ FaultChannelShortToBattery1 : 9|1@1+ (1,0) [0.0|1.0] "" Vector__XXX
 SG_ FaultChannelOverCurrent2 : 10|1@1+ (1,0) [0.0|1.0] "" Vector__XXX
 SG_ FaultChannelI2T2 : 11|1@1+ (1,0) [0.0|1.0] "" Vector__XXX
 SG_ FaultChannelOverTemperature2 : 12|1@1+ (1,0) [0.0|1.0] "" Vector__XXX
 SG_ FaultChannelOpenLoad2 : 13|1@1+ (1,0) [0.0|1.0] "" Vector__XXX
 SG_ FaultChannelShortToBattery2 : 14|1@1+ (1,0) [0.0|1.0] "" Vector__XXX
 SG_ FaultChannelOverCurrent3 : 15|1@1+ (1,0) [0.0|1.0] "" Vector__XXX
 SG_ FaultChannelI2T3 : 16|1@1+ (1,0) [0.0|1.0] "" Vector__XXX
 SG_ FaultChannelOverTemperature3 : 17|1@1+ (1,0) [0.0|1.0] "" Vector__XXX
 SG_ FaultChannelOpenLoad3 : 18|1@1+ (1,0) [0.0|1.0] "" Vector__XXX
 SG_ FaultChannelShortToBattery3 : 19|1@1+ (1,0) [0.0|1.0] "" Vector__XXX
 SG_ FaultChannelOverCurrent4 : 20|1@1+ (1,0) [0.0|1.0] "" Vector__XXX
 SG_ FaultChannelI2T4 : 21|1@1+ (1,0) [0.0|1.0] "" Vector__XXX
 SG_ FaultChannelOverTemperature4 : 22|1@1+ (1,0) [0.0|1.0] "" Vector__XXX
 SG_ FaultChannelOpenLoad4 : 23|1@1+ (1,0) [0.0|1.0] "" Vector__XXX
 SG_ FaultChannelShortToBattery4 : 24|1@1+ (1,0) [0.0|1.0] "" Vector__XXX
 SG_ FaultChannelOverCurrent5 : 25|1@1+ (1,0) [0.0|1.0] "" Vector__XXX
 SG_ FaultChannelI2T5 : 26|1@1+ (1,0) [0.0|1.0] "" Vector__XXX
 SG_ FaultChannelOverTemperature5 : 27|1@1+ (1,0) [0.0|1.0] "" Vector__XXX
 SG_ FaultChannelOpenLoad5 : 28|1@1+ (1,0) [0.0|1.0] "" Vector__XXX
 SG_ FaultChannelShortToBattery5 : 29|1@1+ (1,0) [0.0|1.0] "" Vector__XXX
 SG_ FaultChannelOverCurrent6 : 30|1@1+ (1,0) [0.0|1.0] "" Vector__XXX
 SG_ FaultChannelI2T6 : 31|1@1+ (1,0) [0.0|1.0] "" Vector__XXX
 SG_ FaultChannelOverTemperature6 : 32|1@1+ (1,0) [0.0|1.0] "" Vector__XXX
 SG_ FaultChannelOpenLoad6 : 33|1@1+ (1,0) [0.0|1.0] "" Vector__XXX
 SG_ FaultChannelShortToBattery6 : 34|1@1+ (1,0) [0.0|1.0] "" Vector__XXX
 SG_ FaultChannelOverCurrent7 : 35|1@1+ (1,0) [0.0|1.0] "" Vector__XXX
 SG_ FaultChannelI2T7 : 36|1@1+ (1,0) [0.0|1.0] "" Vector__XXX
 SG_ FaultChannelOverTemperature7 : 37|1@1+ (1,0) [0.0|1.0] "" Vector__XXX
 SG_ FaultChannelOpenLoad7 : 38|1@1+ (1,0) [0.0|1.0] "" Vector__XXX
 SG_ FaultChannelShortToBattery7 : 39|1@1+ (1,0) [0.0|1.0] "" Vector__XXX
 SG_ FaultChannelOverCurrent8 : 40|1@1+ (1,0) [0.0|1.0] "" Vector__XXX
 SG_ FaultChannelI2T8 : 41|1@1+ (1,0) [0.0|1.0] "" Vector__XXX
 SG_ FaultChannelOverTemperature8 : 42|1@1+ (1,0) [0.0|1.0] "" Vector__XXX
 SG_ FaultChannelOpenLoad8 : 43|1@1+ (1,0) [0.0|1.0] "" Vector__XXX
 SG_ FaultChannelShortToBattery8 : 44|1@1+ (1,0) [0.0|1.0] "" Vector__XXX
 SG_ FaultChannelOverCurrent9 : 45|1@1+ (1,0) [0.0|1.0] "" Vector__XXX
 SG_ FaultChannelI2T9 : 46|1@1+ (1,0) [0.0|1.0] "" Vector__XXX
 SG_ FaultChannelOverTemperature9 : 47|1@1+ (1,0) [0.0|1.0] "" Vector__XXX
 SG_ FaultChannelOpenLoad9 : 48|1@1+ (1,0) [0.0|1.0] "" Vector__XXX
 SG_ FaultChannelShortToBattery9 : 49|1@1+ (1,0) [0.0|1.0] "" Vector__XXX
 SG_ FaultChannelOverCurrent10 : 50|1@1+ (1,0) [0.0|1.0] "" Vector__XXX
 SG_ FaultChannelI2T10 : 51|1@1+ (1,0) [0.0|1.0] "" Vector__XXX
 SG_ FaultChannelOverTemperature10 : 52|1@1+ (1,0) [0.0|1.0] "" Vector__XXX
 SG_ FaultChannelOpenLoad10 : 53|1@1+ (1,0) [0.0|1.0] "" Vector__XXX
 SG_ FaultChannelShortToBattery10 : 54|1@1+ (1,0) [0.0|1.0] "" Vector__XXX
 SG_ FaultChannelOverCurrent11 : 55|1@1+ (1,0) [0.0|1.0] "" Vector__XXX
 SG_ FaultChannelI2T11 : 56|1@1+ (1,0) [0.0|1.0] "" Vector__XXX
 SG_ FaultChannelOverTemperature11 : 57|1@1+ (1,0) [0.0|1.0] "" Vector__XXX
 SG_ FaultChannelOpenLoad11 : 58|1@1+ (1,0) [0.0|1.0] "" Vector__XXX
 SG_ FaultChannelShortToBattery11 : 59|1@1+ (1,0) [0.0|1.0] "" Vector__XXX
 SG_ FaultChipVBBUndervoltage0 : 60|1@1+ (1,0) [0.0|1.0] "" Vector__XXX
 SG_ FaultChipSPIError0 : 61|1@1+ (1,0) [0.0|1.0] "" Vector__XXX
 SG_ FaultChipWatchdog0 : 62|1@1+ (1,0) [0.0|1.0] "" Vector__XXX
 SG_ FaultChipVBBUndervoltage1 : 63|1@1+ (1,0) [0.0|1.0] "" Vector__XXX
 SG_ FaultChipSPIError1 : 64|1@1+ (1,0) [0.0|1.0] "" Vector__XXX
 SG_ FaultChipWatchdog1 : 65|1@1+ (1,0) [0.0|1.0] "" Vector__XXX
 SG_ FaultChipVBBUndervoltage2 : 66|1@1+ (1,0) [0.0|1.0] "" Vector__XXX
 SG_ FaultChipSPIError2 : 67|1@1+ (1,0) [0.0|1.0] "" Vector__XXX
 SG_ FaultChipWatchdog2 : 68|1@1+ (1,0) [0.0|1.0] "" Vector__XXX
 SG_ FaultChipVBBUndervoltage3 : 69|1@1+ (1,0) [0.0|1.0] "" Vector__XXX
 SG_ FaultChipSPIError3 : 70|1@1+ (1,0) [0.0|1.0] "" Vector__XXX
 SG_ FaultChipWatchdog3 : 71|1@1+ (1,0) [0.0|1.0] "" Vector__XXX
 SG_ FaultChipVBBUndervoltage4 : 72|1@1+ (1,0) [0.0|1.0] "" Vector__XXX
 SG_ FaultChipSPIError4 : 73|1@1+ (1,0) [0.0|1.0] "" Vector__XXX
 SG_ FaultChipWatchdog4 : 74|1@1+ (1,0) [0.0|1.0] "" Vector__XXX
 SG_ FaultChipVBBUndervoltage5 : 75|1@1+ (1,0) [0.0|1.0] "" Vector__XXX
 SG_ FaultChipSPIError5 : 76|1@1+ (1,0) [0.0|1.0] "" Vector__XXX
 SG_ FaultChipWatchdog5 : 77|1@1+ (1,0) [0.0|1.0] "" Vector__XXX
 SG_ WarningBlownFuse : 78|1@1+ (1,0) [0.0|1.0] "" Vector__XXX
 SG_ WarningChannelBlownFuse0 : 79|1@1+ (1,0) [0.0|1.0] "" Vector__XXX
 SG_ WarningChannelBlownFuse1 : 80|1@1+ (1,0) [0.0|1.0] "" Vector__XXX
 SG_ WarningChannelBlownFuse2 : 81|1@1+ (1,0) [0.0|1.0] "" Vector__XXX
 SG_ WarningChannelBlownFuse3 : 82|1@1+ (1,0) [0.0|1.0] "" Vector__XXX
 SG_ WarningChannelBlownFuse4 : 83|1@1+ (1,0) [0.0|1.0] "" Vector__XXX
 SG_ WarningChannelBlownFuse5 : 84|1@1+ (1,0) [0.0|1.0] "" Vector__XXX
 SG_ WarningChannelBlownFuse6 : 85|1@1+ (1,0) [0.0|1.0] "" Vector__XXX
 SG_ WarningChannelBlownFuse7 : 86|1@1+ (1,0) [0.0|1.0] "" Vector__XXX
 SG_ WarningChannelBlownFuse8 : 87|1@1+ (1,0) [0.0|1.0] "" Vector__XXX
 SG_ WarningChannelBlownFuse9 : 88|1@1+ (1,0) [0.0|1.0] "" Vector__XXX
 SG_ WarningChannelBlownFuse10 : 89|1@1+ (1,0) [0.0|1.0] "" Vector__XXX
 SG_ WarningChannelBlownFuse11 : 90|1@1+ (1,0) [0.0|1.0] "" Vector__XXX
 SG_ ChannelEnabled0 : 91|1@1+ (1,0) [0.0|1.0] "" Vector__XXX
 SG_ ChannelEnabled1 : 92|1@1+ (1,0) [0.0|1.0] "" Vector__XXX
 SG_ ChannelEnabled2 : 93|1@1+ (1,0) [0.0|1.0] "" Vector__XXX
 SG_ ChannelEnabled3 : 94|1@1+ (1,0) [0.0|1.0] "" Vector__XXX
 SG_ ChannelEnabled4 : 95|1@1+ (1,0) [0.0|1.0] "" Vector__XXX
 SG_ ChannelEnabled5 : 96|1@1+ (1,0) [0.0|1.0] "" Vector__XXX
 SG_ ChannelEnabled6 : 97|1@1+ (1,0) [0.0|1.0] "" Vector__XXX
 SG_ ChannelEnabled7 : 98|1@1+ (1,0) [0.0|1.0] "" Vector__XXX
 SG_ ChannelEnabled8 : 99|1@1+ (1,0) [0.0|1.0] "" Vector__XXX
 SG_ ChannelEnabled9 : 100|1@1+ (1,0) [0.0|1.0] "" Vector__XXX
 SG_ ChannelEnabled10 : 101|1@1+ (1,0) [0.0|1.0] "" Vector__XXX
 SG_ ChannelEnabled11 : 102|1@1+ (1,0) [0.0|1.0] "" Vector__XXX

BO_ 161 PDUCurrentData: 20 PDU
 SG_ ChannelCurrent0 : 0|12@1+ (0.01,0) [0|40.95] "A" Vector__XXX
 SG_ ChannelCurrent1 : 12|12@1+ (0.01,0) [0|40.95] "A" Vector__XXX
 SG_ ChannelCurrent2 : 24|12@1+ (0.01,0) [0|40.95] "A" Vector__XXX
 SG_ ChannelCurrent3 : 36|12@1+ (0.01,0) [0|40.95] "A" Vector__XXX
 SG_ ChannelCurrent4 : 48|12@1+ (0.01,0) [0|40.95] "A" Vector__XXX
 SG_ ChannelCurrent5 : 60|12@1+ (0.01,0) [0|40.95] "A" Vector__XXX
 SG_ ChannelCurrent6 : 72|12@1+ (0.01,0) [0|40.95] "A" Vector__XXX
 SG_ ChannelCurrent7 : 84|12@1+ (0.01,0) [0|40.95] "A" Vector__XXX
 SG_ ChannelCurrent8 : 96|12@1+ (0.01,0) [0|40.95] "A" Vector__XXX
 SG_ ChannelCurrent9 : 108|12@1+ (0.01,0) [0|40.95] "A" Vector__XXX
 SG_ ChannelCurrent10 : 120|12@1+ (0.01,0) [0|40.95] "A" Vector__XXX
 SG_ ChannelCurrent11 : 132|12@1+ (0.01,0) [0|40.95] "A" Vector__XXX
 SG_ TotalCurrent : 144|14@1+ (0.01,0) [0|163.83] "A" Vector__XXX

BO_ 162 PDUVoltageData: 20 PDU
 SG_ InputVoltage : 0|10@1+ (0.05,0) [0|51.150000000000006] "V" Vector__XXX
 SG_ ChannelVoltage0 : 10|10@1+ (0.05,0) [0|51.150000000000006] "V" Vector__XXX
 SG_ ChannelVoltage1 : 20|10@1+ (0.05,0) [0|51.150000000000006] "V" Vector__XXX
 SG_ ChannelVoltage2 : 30|10@1+ (0.05,0) [0|51.150000000000006] "V" Vector__XXX
 SG_ ChannelVoltage3 : 40|10@1+ (0.05,0) [0|51.150000000000006] "V" Vector__XXX
 SG_ ChannelVoltage4 : 50|10@1+ (0.05,0) [0|51.150000000000006] "V" Vector__XXX
 SG_ ChannelVoltage5 : 60|10@1+ (0.05,0) [0|51.150000000000006] "V" Vector__XXX
 SG_ ChannelVoltage6 : 70|10@1+ (0.05,0) [0|51.150000000000006] "V" Vector__XXX
 SG_ ChannelVoltage7 : 80|10@1+ (0.05,0) [0|51.150000000000006] "V" Vector__XXX
 SG_ ChannelVoltage8 : 90|10@1+ (0.05,0) [0|51.150000000000006] "V" Vector__XXX
 SG_ ChannelVoltage9 : 100|10@1+ (0.05,0) [0|51.150000000000006] "V" Vector__XXX
 SG_ ChannelVoltage10 : 110|10@1+ (0.05,0) [0|51.150000000000006] "V" Vector__XXX
 SG_ ChannelVoltage11 : 120|10@1+ (0.05,0) [0|51.150000000000006] "V" Vector__XXX

BO_ 163 PDUTemperatureData: 20 PDU
 SG_ ChannelTemperature0 : 0|13@1+ (0.05,-40) [-40|200] "degC" Vector__XXX
 SG_ ChannelTemperature1 : 13|13@1+ (0.05,-40) [-40|200] "degC" Vector__XXX
 SG_ ChannelTemperature2 : 26|13@1+ (0.05,-40) [-40|200] "degC" Vector__XXX
 SG_ ChannelTemperature3 : 39|13@1+ (0.05,-40) [-40|200] "degC" Vector__XXX
 SG_ ChannelTemperature4 : 52|13@1+ (0.05,-40) [-40|200] "degC" Vector__XXX
 SG_ ChannelTemperature5 : 65|13@1+ (0.05,-40) [-40|200] "degC" Vector__XXX
 SG_ ChannelTemperature6 : 78|13@1+ (0.05,-40) [-40|200] "degC" Vector__XXX
 SG_ ChannelTemperature7 : 91|13@1+ (0.05,-40) [-40|200] "degC" Vector__XXX
 SG_ ChannelTemperature8 : 104|13@1+ (0.05,-40) [-40|200] "degC" Vector__XXX
 SG_ ChannelTemperature9 : 117|13@1+ (0.05,-40) [-40|200] "degC" Vector__XXX
 SG_ ChannelTemperature10 : 130|13@1+ (0.05,-40) [-40|200] "degC" Vector__XXX
 SG_ ChannelTemperature11 : 143|13@1+ (0.05,-40) [-40|200] "degC" Vector__XXX

BO_ 164 PDUOverCurrentSnapshot: 12 PDU
 SG_ FaultOverCurrent : 0|1@1+ (1,0) [0.0|1.0] "" Vector__XXX
 SG_ FaultI2T : 1|1@1+ (1,0) [0.0|1.0] "" Vector__XXX
 SG_ TripCurrentSaturated : 2|1@1+ (1,0) [0.0|1.0] "" Vector__XXX
 SG_ ChannelIndex : 3|4@1+ (1,0) [0|11] "" Vector__XXX
 SG_ CaptureTimeMs : 7|32@1+ (1,0) [0|4294967295] "ms" Vector__XXX
 SG_ CurrentSampleAgeMs : 39|16@1+ (1,0) [0|65535] "ms" Vector__XXX
 SG_ TripCurrent : 55|16@1+ (0.01,0) [0|655.35] "A" Vector__XXX

CM_ BO_ 81 "2027 team-defined layout; physical values use the shared scaling conventions.";
CM_ SG_ 81 CurrentOverride "Requests a current override when enabled; BPS firmware defines handling.";
CM_ SG_ 81 TemperatureOverrideMask "Bit 0 selects temperature 1; bit 31 selects temperature 32. Set bit requests the corresponding override.";
CM_ SG_ 81 VoltageOverrideMask "Bit 0 selects tap 1; bit 31 selects tap 32. Set bit requests the corresponding override.";
CM_ SG_ 81 MPPTChargeScheme "MPPTChargeScheme";
CM_ SG_ 81 Mode "Mode";
CM_ BO_ 82 "2027 team-defined layout; physical values use the shared scaling conventions.";
CM_ SG_ 82 Enable "Enable";
CM_ SG_ 82 ChannelIndex "Zero-based channel index: 0 selects Channel0; 11 selects Channel11.";
CM_ BO_ 83 "2027 team-defined layout; physical values use the shared scaling conventions.";
CM_ SG_ 83 CommandSource "CommandSource";
CM_ BO_ 84 "Defined empty trigger: request a sweep from all MPPTs through MPPTInterface. Zero-byte CAN-FD payload.";
CM_ BO_ 85 "Triggered balancing request. BPS evaluates safety conditions independently; manual selection does not bypass protection.";
CM_ SG_ 85 ManualCellMask "Manual mode only: bit 0 selects cell 00; bit 31 selects cell 31.";
CM_ SG_ 85 BalancingMode "Off, automatic selection by BPS, or manual selection by mask.";
CM_ BO_ 96 "BPS faults, warnings, state, contactors, control permissions, MPPT limits, and fan tachometers. Pack measurements are in BPSPackData (0x070). CAN-FD; no transmit period assigned yet.";
CM_ SG_ 96 BPSFanTach "BPSFanTach";
CM_ SG_ 96 BatteryFanTach2 "BatteryFan2Tach";
CM_ SG_ 96 BatteryFanTach1 "BatteryFan1Tach";
CM_ SG_ 96 MPPTCurrentLimit "MPPTCurrentLimit";
CM_ SG_ 96 MPPTVoltageLimit "MPPTVoltageLimit";
CM_ SG_ 96 BalancingActive "1 when BPS reports at least one cell group actively balancing; 0 otherwise.";
CM_ SG_ 96 MotorPrechargeRelay "MotorPrechargeRelay";
CM_ SG_ 96 MainPrechargeRelay "MainPrechargeRelay";
CM_ SG_ 96 HVNegativeContactor "HVNegativeContactor";
CM_ SG_ 96 MotorContactor "MotorContactor";
CM_ SG_ 96 HVPositiveContactor "HVPositiveContactor";
CM_ SG_ 96 RegenSafe "BPS permission for regenerative charging, independently evaluated. 0 means not permitted.";
CM_ SG_ 96 MPPTSetMode "MPPTSetMode";
CM_ SG_ 96 ChargeSafe "BPS permission for charging from charger or solar sources, subject to charging-specific safety checks. 0 means not permitted.";
CM_ SG_ 96 DischargeSafe "BPS permission for battery discharge, including motor drive and HV-to-LV DC-DC load. 0 means not permitted.";
CM_ SG_ 96 WarningBPSFan "WarningBPSFan";
CM_ SG_ 96 WarningBatteryFan2 "WarningBatteryFan2";
CM_ SG_ 96 WarningBatteryFan1 "WarningBatteryFan1";
CM_ SG_ 96 WarningDischargeOverTemperature "WarningDischargeOverTemperature";
CM_ SG_ 96 WarningChargeOverTemperature "WarningChargeOverTemperature";
CM_ SG_ 96 WarningOverVoltage "WarningOverVoltage";
CM_ SG_ 96 WarningUnderVoltage "WarningUnderVoltage";
CM_ SG_ 96 WarningSMBCommunication "WarningSMBCommunication";
CM_ SG_ 96 FaultMotorPrechargeVoltage "FaultMotorPrechargeVoltage";
CM_ SG_ 96 FaultMainPrechargeVoltage "FaultMainPrechargeVoltage";
CM_ SG_ 96 FaultMotorVoltage "FaultMotorVoltage";
CM_ SG_ 96 FaultMainVoltage "FaultMainVoltage";
CM_ SG_ 96 FaultMotorPrechargeTimeout "FaultMotorPrechargeTimeout";
CM_ SG_ 96 FaultMainPrechargeTimeout "FaultMainPrechargeTimeout";
CM_ SG_ 96 FaultChargerEstop "FaultChargerEstop";
CM_ SG_ 96 FaultBatteryEstop "FaultBatteryEstop";
CM_ SG_ 96 FaultExternalEstop "FaultExternalEstop";
CM_ SG_ 96 FaultDriverEstop "FaultDriverEstop";
CM_ SG_ 96 FaultMotorPrechargeRelayMismatch "FaultMotorPrechargeRelayMismatch";
CM_ SG_ 96 FaultMainPrechargeRelayMismatch "FaultMainPrechargeRelayMismatch";
CM_ SG_ 96 FaultHVNegativeContactorMismatch "FaultHVNegativeContactorMismatch";
CM_ SG_ 96 FaultMotorContactorMismatch "FaultMotorContactorMismatch";
CM_ SG_ 96 FaultHVPositiveContactorMismatch "FaultHVPositiveContactorMismatch";
CM_ SG_ 96 FaultDischargeOverCurrent "FaultDischargeOverCurrent";
CM_ SG_ 96 FaultChargeOverCurrent "FaultChargeOverCurrent";
CM_ SG_ 96 FaultUnderVoltage "FaultUnderVoltage";
CM_ SG_ 96 FaultOverVoltage "FaultOverVoltage";
CM_ SG_ 96 FaultOverTemperature "FaultOverTemperature";
CM_ SG_ 96 FaultSummary "FaultSummary";
CM_ SG_ 96 Status "Status";
CM_ BO_ 97 "2027 team-defined layout; physical values use the shared scaling conventions.";
CM_ SG_ 97 RearPressure "RearPressure";
CM_ SG_ 97 FrontPressure "FrontPressure";
CM_ SG_ 97 AcceleratorRedundantPosition "AcceleratorRedundantPosition";
CM_ SG_ 97 AcceleratorMainPosition "AcceleratorMainPosition";
CM_ SG_ 97 HandbrakePressureSwitch "HandbrakePressureSwitch";
CM_ SG_ 97 FrontPressureSwitch "FrontPressureSwitch";
CM_ SG_ 97 BrakeActive "BrakeActive";
CM_ SG_ 97 WarningPressureSwitchMismatch "WarningPressureSwitchMismatch";
CM_ SG_ 97 WarningRedundantAcceleratorDisco "WarningRedundantAcceleratorDisconnected";
CM_ SG_ 97 WarningMainAcceleratorDisconnect "WarningMainAcceleratorDisconnected";
CM_ SG_ 97 FaultNoAccelerator "FaultNoAccelerator";
CM_ SG_ 97 Status "Status";
CM_ BO_ 98 "2027 team-defined layout; physical values use the shared scaling conventions.";
CM_ SG_ 98 Headlights "Headlights";
CM_ SG_ 98 PushToTalk "PushToTalk";
CM_ SG_ 98 Horn "Horn";
CM_ SG_ 98 RegenActivate "RegenActivate";
CM_ SG_ 98 RegenEnable "RegenEnable";
CM_ SG_ 98 RightTurnSignal "RightTurnSignal";
CM_ SG_ 98 LeftTurnSignal "LeftTurnSignal";
CM_ SG_ 98 Hazards "Hazards";
CM_ SG_ 98 Gear "Gear";
CM_ SG_ 98 IgnitionDrive "IgnitionDrive";
CM_ SG_ 98 IgnitionCharge "IgnitionCharge";
CM_ SG_ 98 IgnitionLV "IgnitionLV";
CM_ BO_ 99 "2027 team-defined layout; physical values use the shared scaling conventions.";
CM_ SG_ 99 MotorFanTach "MotorFanTach";
CM_ SG_ 99 MotorControllerFanTach "MotorControllerFanTach";
CM_ SG_ 99 MotorCommandSource "MotorCommandSource";
CM_ SG_ 99 FSMGear "FSMGear";
CM_ SG_ 99 FSMDriverRegenRequest "FSMDriverRegenRequest";
CM_ SG_ 99 FSMDriverRegenEnable "FSMDriverRegenEnable";
CM_ SG_ 99 FSMBPSRegenOK "FSMBPSRegenOK";
CM_ SG_ 99 FSMBPSDriveOK "FSMBPSDriveOK";
CM_ SG_ 99 FSMBrake "FSMBrake";
CM_ SG_ 99 State "State";
CM_ SG_ 99 RegenEnabled "RegenEnabled";
CM_ SG_ 99 WarningMotorFan "WarningMotorFan";
CM_ SG_ 99 WarningMotorControllerFan "WarningMotorControllerFan";
CM_ SG_ 99 WarningDirectionChangeLockout "WarningDirectionChangeLockout";
CM_ SG_ 99 WarningTipping "WarningTipping";
CM_ SG_ 99 FaultPedalsWatchdog "FaultPedalsWatchdog";
CM_ SG_ 99 FaultDriverInputWatchdog "FaultDriverInputWatchdog";
CM_ SG_ 99 FaultBPSWatchdog "FaultBPSWatchdog";
CM_ SG_ 99 FaultMotorControllerWatchdog "FaultMotorControllerWatchdog";
CM_ SG_ 99 FaultPedals "FaultPedals";
CM_ SG_ 99 FaultBPS "FaultBPS";
CM_ SG_ 99 FaultMotor "FaultMotor";
CM_ SG_ 99 Status "Status";
CM_ BO_ 112 "BPS pack electrical measurements: cell-sum and main/motor battery and precharge voltages, then battery current. Cell-voltage extrema are in BPSVoltageData; temperature summaries are in BPSTemperatureData. Signal encodings unchanged; no transmit period assigned yet.";
CM_ SG_ 112 BatteryCurrent "BatteryCurrent";
CM_ SG_ 112 MotorVoltage "MotorVoltage";
CM_ SG_ 112 MainVoltage "MainVoltage";
CM_ SG_ 112 MotorBatteryVoltage "MotorBatteryVoltage";
CM_ SG_ 112 MainBatteryVoltage "MainBatteryVoltage";
CM_ SG_ 112 CellSumVoltage "Sum of the 32 cell-tap voltages, independent of precharge measurements. Bulk voltage encoding: unsigned 12 bits, 0.05 V/bit, offset 0 V.";
CM_ BO_ 113 "BPS individual cell voltages followed by minimum/maximum cell voltage; unchanged physical encodings.";
CM_ SG_ 113 MaxCellVoltage "MaxCellVoltage";
CM_ SG_ 113 MinCellVoltage "MinCellVoltage";
CM_ SG_ 113 CellVoltage31 "CellVoltage31";
CM_ SG_ 113 CellVoltage30 "CellVoltage30";
CM_ SG_ 113 CellVoltage29 "CellVoltage29";
CM_ SG_ 113 CellVoltage28 "CellVoltage28";
CM_ SG_ 113 CellVoltage27 "CellVoltage27";
CM_ SG_ 113 CellVoltage26 "CellVoltage26";
CM_ SG_ 113 CellVoltage25 "CellVoltage25";
CM_ SG_ 113 CellVoltage24 "CellVoltage24";
CM_ SG_ 113 CellVoltage23 "CellVoltage23";
CM_ SG_ 113 CellVoltage22 "CellVoltage22";
CM_ SG_ 113 CellVoltage21 "CellVoltage21";
CM_ SG_ 113 CellVoltage20 "CellVoltage20";
CM_ SG_ 113 CellVoltage19 "CellVoltage19";
CM_ SG_ 113 CellVoltage18 "CellVoltage18";
CM_ SG_ 113 CellVoltage17 "CellVoltage17";
CM_ SG_ 113 CellVoltage16 "CellVoltage16";
CM_ SG_ 113 CellVoltage15 "CellVoltage15";
CM_ SG_ 113 CellVoltage14 "CellVoltage14";
CM_ SG_ 113 CellVoltage13 "CellVoltage13";
CM_ SG_ 113 CellVoltage12 "CellVoltage12";
CM_ SG_ 113 CellVoltage11 "CellVoltage11";
CM_ SG_ 113 CellVoltage10 "CellVoltage10";
CM_ SG_ 113 CellVoltage09 "CellVoltage09";
CM_ SG_ 113 CellVoltage08 "CellVoltage08";
CM_ SG_ 113 CellVoltage07 "CellVoltage07";
CM_ SG_ 113 CellVoltage06 "CellVoltage06";
CM_ SG_ 113 CellVoltage05 "CellVoltage05";
CM_ SG_ 113 CellVoltage04 "CellVoltage04";
CM_ SG_ 113 CellVoltage03 "CellVoltage03";
CM_ SG_ 113 CellVoltage02 "CellVoltage02";
CM_ SG_ 113 CellVoltage01 "CellVoltage01";
CM_ SG_ 113 CellVoltage00 "CellVoltage00";
CM_ SG_ 113 MaxCellVoltageIndex "Zero-based cell index (0-31) corresponding to MaxCellVoltage.";
CM_ SG_ 113 MinCellVoltageIndex "Zero-based cell index (0-31) corresponding to MinCellVoltage.";
CM_ BO_ 114 "BPS individual cell temperatures followed by maximum/average battery temperature; unchanged physical encodings.";
CM_ SG_ 114 AverageBatteryTemperature "AverageBatteryTemperature";
CM_ SG_ 114 MaxBatteryTemperature "MaxBatteryTemperature";
CM_ SG_ 114 CellTemperature31 "CellTemperature31";
CM_ SG_ 114 CellTemperature30 "CellTemperature30";
CM_ SG_ 114 CellTemperature29 "CellTemperature29";
CM_ SG_ 114 CellTemperature28 "CellTemperature28";
CM_ SG_ 114 CellTemperature27 "CellTemperature27";
CM_ SG_ 114 CellTemperature26 "CellTemperature26";
CM_ SG_ 114 CellTemperature25 "CellTemperature25";
CM_ SG_ 114 CellTemperature24 "CellTemperature24";
CM_ SG_ 114 CellTemperature23 "CellTemperature23";
CM_ SG_ 114 CellTemperature22 "CellTemperature22";
CM_ SG_ 114 CellTemperature21 "CellTemperature21";
CM_ SG_ 114 CellTemperature20 "CellTemperature20";
CM_ SG_ 114 CellTemperature19 "CellTemperature19";
CM_ SG_ 114 CellTemperature18 "CellTemperature18";
CM_ SG_ 114 CellTemperature17 "CellTemperature17";
CM_ SG_ 114 CellTemperature16 "CellTemperature16";
CM_ SG_ 114 CellTemperature15 "CellTemperature15";
CM_ SG_ 114 CellTemperature14 "CellTemperature14";
CM_ SG_ 114 CellTemperature13 "CellTemperature13";
CM_ SG_ 114 CellTemperature12 "CellTemperature12";
CM_ SG_ 114 CellTemperature11 "CellTemperature11";
CM_ SG_ 114 CellTemperature10 "CellTemperature10";
CM_ SG_ 114 CellTemperature09 "CellTemperature09";
CM_ SG_ 114 CellTemperature08 "CellTemperature08";
CM_ SG_ 114 CellTemperature07 "CellTemperature07";
CM_ SG_ 114 CellTemperature06 "CellTemperature06";
CM_ SG_ 114 CellTemperature05 "CellTemperature05";
CM_ SG_ 114 CellTemperature04 "CellTemperature04";
CM_ SG_ 114 CellTemperature03 "CellTemperature03";
CM_ SG_ 114 CellTemperature02 "CellTemperature02";
CM_ SG_ 114 CellTemperature01 "CellTemperature01";
CM_ SG_ 114 CellTemperature00 "CellTemperature00";
CM_ SG_ 114 MaxBatteryTemperatureIndex "Zero-based cell index (0-31) corresponding to MaxBatteryTemperature.";
CM_ BO_ 115 "PLACEHOLDER: signals and payload length are not defined; zero DLC is a drafting marker, not an approved transmit layout. Four SMB status bitmaps: widths and bit definitions pending.";
CM_ BO_ 116 "Cyclic BPS report mirroring the BPSCommand payload: Mode, MPPTChargeScheme, VoltageOverrideMask, TemperatureOverrideMask, and CurrentOverride. Reports command values held by BPS; does not imply successful application or act as a per-request acknowledgement. Cyclic report every 1000 ms.";
CM_ SG_ 116 CurrentOverride "Requests a current override when enabled; BPS firmware defines handling.";
CM_ SG_ 116 TemperatureOverrideMask "Bit 0 selects temperature 1; bit 31 selects temperature 32. Set bit requests the corresponding override.";
CM_ SG_ 116 VoltageOverrideMask "Bit 0 selects tap 1; bit 31 selects tap 32. Set bit requests the corresponding override.";
CM_ SG_ 116 MPPTChargeScheme "MPPTChargeScheme";
CM_ SG_ 116 Mode "Mode";
CM_ BO_ 117 "Latch once when BPS transitions from no active faults to any active fault, before opening contactors where possible. Send immediately, then every 1000 ms only while any BPS fault remains active. Keep captured samples frozen; never replace them with post-trip zeros. Rearm after all faults clear. Triggered transmission with a 1000 ms active-fault repeat interval; no transmission outside the send condition. Fault bits record the first fault state. BatteryCurrent preserves the live message scaling. CurrentSampleAgeMs describes sampling latency; this is not a guaranteed instantaneous peak measurement.";
CM_ SG_ 117 BatteryCurrent "BatteryCurrent";
CM_ SG_ 117 CaptureTimeMs "BPS monotonic uptime at fault detection, wraps at 2^32 ms; independent of legacy TimestampSync ticks.";
CM_ SG_ 117 CurrentValid "1 only if BatteryCurrent was sampled successfully before capture; otherwise ignore BatteryCurrent and CurrentSampleAgeMs.";
CM_ SG_ 117 FaultMotorPrechargeVoltage "FaultMotorPrechargeVoltage";
CM_ SG_ 117 FaultMainPrechargeVoltage "FaultMainPrechargeVoltage";
CM_ SG_ 117 FaultMotorVoltage "FaultMotorVoltage";
CM_ SG_ 117 FaultMainVoltage "FaultMainVoltage";
CM_ SG_ 117 FaultMotorPrechargeTimeout "FaultMotorPrechargeTimeout";
CM_ SG_ 117 FaultMainPrechargeTimeout "FaultMainPrechargeTimeout";
CM_ SG_ 117 FaultChargerEstop "FaultChargerEstop";
CM_ SG_ 117 FaultBatteryEstop "FaultBatteryEstop";
CM_ SG_ 117 FaultExternalEstop "FaultExternalEstop";
CM_ SG_ 117 FaultDriverEstop "FaultDriverEstop";
CM_ SG_ 117 FaultMotorPrechargeRelayMismatch "FaultMotorPrechargeRelayMismatch";
CM_ SG_ 117 FaultMainPrechargeRelayMismatch "FaultMainPrechargeRelayMismatch";
CM_ SG_ 117 FaultHVNegativeContactorMismatch "FaultHVNegativeContactorMismatch";
CM_ SG_ 117 FaultMotorContactorMismatch "FaultMotorContactorMismatch";
CM_ SG_ 117 FaultHVPositiveContactorMismatch "FaultHVPositiveContactorMismatch";
CM_ SG_ 117 FaultDischargeOverCurrent "FaultDischargeOverCurrent";
CM_ SG_ 117 FaultChargeOverCurrent "FaultChargeOverCurrent";
CM_ SG_ 117 FaultUnderVoltage "FaultUnderVoltage";
CM_ SG_ 117 FaultOverVoltage "FaultOverVoltage";
CM_ SG_ 117 FaultOverTemperature "FaultOverTemperature";
CM_ SG_ 117 FaultSummary "FaultSummary";
CM_ BO_ 118 "Latch once when BPS transitions from no active faults to any active fault, before opening contactors where possible. Send immediately, then every 1000 ms only while any BPS fault remains active. Keep captured samples frozen; never replace them with post-trip zeros. Rearm after all faults clear. Triggered transmission with a 1000 ms active-fault repeat interval; no transmission outside the send condition. The last completed scan available at fault detection is frozen, not acquired after shutdown. Scaling and offsets match BPSVoltageData.";
CM_ SG_ 118 CellVoltage31 "CellVoltage31";
CM_ SG_ 118 CellVoltage30 "CellVoltage30";
CM_ SG_ 118 CellVoltage29 "CellVoltage29";
CM_ SG_ 118 CellVoltage28 "CellVoltage28";
CM_ SG_ 118 CellVoltage27 "CellVoltage27";
CM_ SG_ 118 CellVoltage26 "CellVoltage26";
CM_ SG_ 118 CellVoltage25 "CellVoltage25";
CM_ SG_ 118 CellVoltage24 "CellVoltage24";
CM_ SG_ 118 CellVoltage23 "CellVoltage23";
CM_ SG_ 118 CellVoltage22 "CellVoltage22";
CM_ SG_ 118 CellVoltage21 "CellVoltage21";
CM_ SG_ 118 CellVoltage20 "CellVoltage20";
CM_ SG_ 118 CellVoltage19 "CellVoltage19";
CM_ SG_ 118 CellVoltage18 "CellVoltage18";
CM_ SG_ 118 CellVoltage17 "CellVoltage17";
CM_ SG_ 118 CellVoltage16 "CellVoltage16";
CM_ SG_ 118 CellVoltage15 "CellVoltage15";
CM_ SG_ 118 CellVoltage14 "CellVoltage14";
CM_ SG_ 118 CellVoltage13 "CellVoltage13";
CM_ SG_ 118 CellVoltage12 "CellVoltage12";
CM_ SG_ 118 CellVoltage11 "CellVoltage11";
CM_ SG_ 118 CellVoltage10 "CellVoltage10";
CM_ SG_ 118 CellVoltage09 "CellVoltage09";
CM_ SG_ 118 CellVoltage08 "CellVoltage08";
CM_ SG_ 118 CellVoltage07 "CellVoltage07";
CM_ SG_ 118 CellVoltage06 "CellVoltage06";
CM_ SG_ 118 CellVoltage05 "CellVoltage05";
CM_ SG_ 118 CellVoltage04 "CellVoltage04";
CM_ SG_ 118 CellVoltage03 "CellVoltage03";
CM_ SG_ 118 CellVoltage02 "CellVoltage02";
CM_ SG_ 118 CellVoltage01 "CellVoltage01";
CM_ SG_ 118 CellVoltage00 "CellVoltage00";
CM_ SG_ 118 SampleValidMask "Bit 0 corresponds to cell 00; bit 31 to cell 31. Clear bits mean unavailable readings and their encoded values must be ignored.";
CM_ BO_ 119 "Latch once when BPS transitions from no active faults to any active fault, before opening contactors where possible. Send immediately, then every 1000 ms only while any BPS fault remains active. Keep captured samples frozen; never replace them with post-trip zeros. Rearm after all faults clear. Triggered transmission with a 1000 ms active-fault repeat interval; no transmission outside the send condition. The last completed scan available at fault detection is frozen, not acquired after shutdown. Scaling and offsets match BPSTemperatureData.";
CM_ SG_ 119 CellTemperature31 "CellTemperature31";
CM_ SG_ 119 CellTemperature30 "CellTemperature30";
CM_ SG_ 119 CellTemperature29 "CellTemperature29";
CM_ SG_ 119 CellTemperature28 "CellTemperature28";
CM_ SG_ 119 CellTemperature27 "CellTemperature27";
CM_ SG_ 119 CellTemperature26 "CellTemperature26";
CM_ SG_ 119 CellTemperature25 "CellTemperature25";
CM_ SG_ 119 CellTemperature24 "CellTemperature24";
CM_ SG_ 119 CellTemperature23 "CellTemperature23";
CM_ SG_ 119 CellTemperature22 "CellTemperature22";
CM_ SG_ 119 CellTemperature21 "CellTemperature21";
CM_ SG_ 119 CellTemperature20 "CellTemperature20";
CM_ SG_ 119 CellTemperature19 "CellTemperature19";
CM_ SG_ 119 CellTemperature18 "CellTemperature18";
CM_ SG_ 119 CellTemperature17 "CellTemperature17";
CM_ SG_ 119 CellTemperature16 "CellTemperature16";
CM_ SG_ 119 CellTemperature15 "CellTemperature15";
CM_ SG_ 119 CellTemperature14 "CellTemperature14";
CM_ SG_ 119 CellTemperature13 "CellTemperature13";
CM_ SG_ 119 CellTemperature12 "CellTemperature12";
CM_ SG_ 119 CellTemperature11 "CellTemperature11";
CM_ SG_ 119 CellTemperature10 "CellTemperature10";
CM_ SG_ 119 CellTemperature09 "CellTemperature09";
CM_ SG_ 119 CellTemperature08 "CellTemperature08";
CM_ SG_ 119 CellTemperature07 "CellTemperature07";
CM_ SG_ 119 CellTemperature06 "CellTemperature06";
CM_ SG_ 119 CellTemperature05 "CellTemperature05";
CM_ SG_ 119 CellTemperature04 "CellTemperature04";
CM_ SG_ 119 CellTemperature03 "CellTemperature03";
CM_ SG_ 119 CellTemperature02 "CellTemperature02";
CM_ SG_ 119 CellTemperature01 "CellTemperature01";
CM_ SG_ 119 CellTemperature00 "CellTemperature00";
CM_ SG_ 119 SampleValidMask "Bit 0 corresponds to cell 00; bit 31 to cell 31. Clear bits mean unavailable readings and their encoded values must be ignored.";
CM_ BO_ 120 "BPS sends while at least one cell is actively balancing, immediately on start and every 1000 ms while active. Fully paused, complete or blocked sessions are not transmitted.";
CM_ SG_ 120 BlockReason "Primary BPS-reported reason for a block or pause; additional simultaneous reasons may exist.";
CM_ SG_ 120 PausedChipMask "Bit 0 through bit 3 represent BQ79616 chips 0 through 3 reporting a balancing pause.";
CM_ SG_ 120 SelectedCellMask "Selected cell groups: bit 0 is cell 00 and bit 31 is cell 31. Selection does not imply active bleed.";
CM_ SG_ 120 FaultChipMask "Bit 0 through bit 3 represent BQ79616 chips 0 through 3 reporting balancing fault or abort.";
CM_ BO_ 121 "2027 team-defined layout; physical values use the shared scaling conventions.";
CM_ SG_ 121 FanTach "FanTach";
CM_ SG_ 121 SweepingActive "SweepingActive";
CM_ SG_ 121 MPPTSetMode "MPPTSetMode";
CM_ SG_ 121 WarningFan "WarningFan";
CM_ SG_ 121 WarningMPPTCWatchdog "WarningMPPTCWatchdog";
CM_ SG_ 121 WarningMPPTBWatchdog "WarningMPPTBWatchdog";
CM_ SG_ 121 WarningMPPTAWatchdog "WarningMPPTAWatchdog";
CM_ SG_ 121 WarningBPSWatchdog "WarningBPSWatchdog";
CM_ BO_ 130 "HMI and CM5 status from MIKA (combined HMI and telemetry board). Application ID 0x082 and signal layout retained.";
CM_ SG_ 130 CM5FanTach "CM5 cooling fan tachometer: unsigned 12 bits, 5 rpm/bit, offset 0 rpm.";
CM_ SG_ 130 SoCTemperature "User-approved explicit exception: uint8, 0.5 degC/bit, -20 degC offset.";
CM_ SG_ 130 DisplayFrameRate "DisplayFrameRate";
CM_ SG_ 130 DriverCameraConnected "Driver camera connection state: 0 disconnected, 1 connected.";
CM_ SG_ 130 GPSConnected "GPSConnected";
CM_ SG_ 130 ServerConnected "Connection to the telemetry server; independent of internet connectivity.";
CM_ SG_ 130 InternetConnected "InternetConnected";
CM_ SG_ 130 CellularConnected "CellularConnected";
CM_ SG_ 130 WarningRouterDisconnected "WarningRouterDisconnected";
CM_ SG_ 130 WarningRearCameraDisconnected "Rear camera disconnected warning; the driver camera has a separate connected bit.";
CM_ SG_ 130 WarningDisplayDisconnected "WarningDisplayDisconnected";
CM_ SG_ 130 WarningOverTemperature "WarningOverTemperature";
CM_ SG_ 130 WarningTemperature "WarningTemperature";
CM_ BO_ 144 "LVC warnings and discrete states only; no fault bits. HSS warnings describe the single BPS feed HSS. BPSLVBlownFuse uses separate hardware monitoring; the PDU feed is separate.";
CM_ SG_ 144 BPSLVEnabled "Requested enable state of BPS HSS output channel 1; not proof of output voltage.";
CM_ SG_ 144 DCDCEnabled "DC-DC enable state.";
CM_ SG_ 144 WarningBPSLVBlownFuse "Separate hardware fuse monitor on the BPS feed; independent of HSS open-load diagnostics.";
CM_ SG_ 144 WarningNoDCDCOutput "DC-DC output unavailable.";
CM_ SG_ 144 WarningHSSWatchdog "LVC BPS HSS chip diagnostic: Watchdog. SPIError includes MCU-detected SPI/frame/CRC failures.";
CM_ SG_ 144 WarningHSSSPIError "LVC BPS HSS chip diagnostic: SPIError. SPIError includes MCU-detected SPI/frame/CRC failures.";
CM_ SG_ 144 WarningHSSVBBUndervoltage "LVC BPS HSS chip diagnostic: VBBUndervoltage. SPIError includes MCU-detected SPI/frame/CRC failures.";
CM_ SG_ 144 WarningHSSShortToBattery "BPS HSS output ShortToBattery warning; overtemperature combines absolute and relative thermal shutdown.";
CM_ SG_ 144 WarningHSSOpenLoad "BPS HSS output OpenLoad warning; overtemperature combines absolute and relative thermal shutdown.";
CM_ SG_ 144 WarningHSSOverTemperature "BPS HSS output OverTemperature warning; overtemperature combines absolute and relative thermal shutdown.";
CM_ SG_ 144 WarningHSSI2T "BPS HSS output I2T warning; overtemperature combines absolute and relative thermal shutdown.";
CM_ SG_ 144 WarningHSSOverCurrent "BPS HSS output OverCurrent warning; overtemperature combines absolute and relative thermal shutdown.";
CM_ BO_ 145 "10 Hz measured LV currents. BPSLVCurrent belongs to the single populated HSS output; no fictitious PDU HSS channel is reported.";
CM_ SG_ 145 BPSLVCurrent "Measured BPSLVCurrent.";
CM_ SG_ 145 TotalOutputCurrent "Measured TotalOutputCurrent. Independently measured total output, not a sum of HSS channels. The PDU feed is included only through this actual total measurement.";
CM_ SG_ 145 LVBCurrent "Measured LVBCurrent. Positive = battery discharge into LV supply; negative = battery charging.";
CM_ SG_ 145 DCDCCurrent "Measured DCDCCurrent.";
CM_ BO_ 146 "2 Hz LV voltage telemetry. HSS-derived BPSLVVoltage can stop updating when ADC conversion is suspended; consult sample age and chip diagnostics.";
CM_ SG_ 146 BPSLVVoltage "Measured BPSLVVoltage; zero is representable to expose a powered-off output.";
CM_ SG_ 146 PowerSupplyVoltage "Measured PowerSupplyVoltage; zero is representable to expose a powered-off output.";
CM_ SG_ 146 LVBVoltage "Measured LVBVoltage; zero is representable to expose a powered-off output.";
CM_ SG_ 146 DCDCVoltage "Measured DCDCVoltage; zero is representable to expose a powered-off output.";
CM_ BO_ 147 "1 Hz BPS HSS FET temperature; temperature conversions can be suspended in applicable I2T modes; consult sample age and chip diagnostics.";
CM_ SG_ 147 BPSFETTemperature "Internal temperature of the BPS channel power FET, not load/ambient temperature.";
CM_ BO_ 148 "Latch the first overcurrent or I2T trip per output until an explicit firmware fault-reset action. Freeze the last pre-trip current, its age at detection and the sending board monotonic uptime at detection. Reading diagnostic registers does not clear the telemetry latch. Send immediately on a new trip, then every 1000 ms while a trip remains latched. Never overwrite a captured current with post-shutdown zero. No snapshot/event identifier is sent. Capture time resets on board reboot. This records a sampled current, not a guaranteed instantaneous analog peak.";
CM_ SG_ 148 TripCurrent "Captured current; independent record per output; saturation marks a lower bound.";
CM_ SG_ 148 CaptureTimeMs "Board uptime at the first latched trip; wraps at 2^32 ms. Interpret only while a trip flag is set.";
CM_ SG_ 148 TripCurrentSaturated "1 if the captured current is clipped or the sensing path was saturated; the current is then a lower bound, not an exact peak.";
CM_ SG_ 148 FaultI2T "Latched I2T trip for BPS feed.";
CM_ SG_ 148 FaultOverCurrent "Latched OverCurrent trip for BPS feed.";
CM_ BO_ 160 "12 outputs, 6 TPS2HCS08A dual-channel chips. Faults -> warnings -> discrete states. Chip n owns channels 2n-1/2n. Per-channel fuse warnings come from separate hardware. No continuous measurements.";
CM_ SG_ 160 ChannelEnabled11 "Requested channel 11 enable state; not proof of output voltage.";
CM_ SG_ 160 ChannelEnabled10 "Requested channel 10 enable state; not proof of output voltage.";
CM_ SG_ 160 ChannelEnabled9 "Requested channel 9 enable state; not proof of output voltage.";
CM_ SG_ 160 ChannelEnabled8 "Requested channel 8 enable state; not proof of output voltage.";
CM_ SG_ 160 ChannelEnabled7 "Requested channel 7 enable state; not proof of output voltage.";
CM_ SG_ 160 ChannelEnabled6 "Requested channel 6 enable state; not proof of output voltage.";
CM_ SG_ 160 ChannelEnabled5 "Requested channel 5 enable state; not proof of output voltage.";
CM_ SG_ 160 ChannelEnabled4 "Requested channel 4 enable state; not proof of output voltage.";
CM_ SG_ 160 ChannelEnabled3 "Requested channel 3 enable state; not proof of output voltage.";
CM_ SG_ 160 ChannelEnabled2 "Requested channel 2 enable state; not proof of output voltage.";
CM_ SG_ 160 ChannelEnabled1 "Requested channel 1 enable state; not proof of output voltage.";
CM_ SG_ 160 ChannelEnabled0 "Requested channel 0 enable state; not proof of output voltage.";
CM_ SG_ 160 WarningChannelBlownFuse11 "Separate hardware blown-fuse monitor for channel 11; not inferred from HSS open-load fault.";
CM_ SG_ 160 WarningChannelBlownFuse10 "Separate hardware blown-fuse monitor for channel 10; not inferred from HSS open-load fault.";
CM_ SG_ 160 WarningChannelBlownFuse9 "Separate hardware blown-fuse monitor for channel 9; not inferred from HSS open-load fault.";
CM_ SG_ 160 WarningChannelBlownFuse8 "Separate hardware blown-fuse monitor for channel 8; not inferred from HSS open-load fault.";
CM_ SG_ 160 WarningChannelBlownFuse7 "Separate hardware blown-fuse monitor for channel 7; not inferred from HSS open-load fault.";
CM_ SG_ 160 WarningChannelBlownFuse6 "Separate hardware blown-fuse monitor for channel 6; not inferred from HSS open-load fault.";
CM_ SG_ 160 WarningChannelBlownFuse5 "Separate hardware blown-fuse monitor for channel 5; not inferred from HSS open-load fault.";
CM_ SG_ 160 WarningChannelBlownFuse4 "Separate hardware blown-fuse monitor for channel 4; not inferred from HSS open-load fault.";
CM_ SG_ 160 WarningChannelBlownFuse3 "Separate hardware blown-fuse monitor for channel 3; not inferred from HSS open-load fault.";
CM_ SG_ 160 WarningChannelBlownFuse2 "Separate hardware blown-fuse monitor for channel 2; not inferred from HSS open-load fault.";
CM_ SG_ 160 WarningChannelBlownFuse1 "Separate hardware blown-fuse monitor for channel 1; not inferred from HSS open-load fault.";
CM_ SG_ 160 WarningChannelBlownFuse0 "Separate hardware blown-fuse monitor for channel 0; not inferred from HSS open-load fault.";
CM_ SG_ 160 WarningBlownFuse "Aggregate OR of WarningChannelBlownFuse1..12 from the separate hardware channel monitors.";
CM_ SG_ 160 FaultChipWatchdog5 "Chip 5, shared by channels 11/12. SPIError includes MCU-detected SPI/frame/CRC errors.";
CM_ SG_ 160 FaultChipSPIError5 "Chip 5, shared by channels 11/12. SPIError includes MCU-detected SPI/frame/CRC errors.";
CM_ SG_ 160 FaultChipVBBUndervoltage5 "Chip 5, shared by channels 11/12. SPIError includes MCU-detected SPI/frame/CRC errors.";
CM_ SG_ 160 FaultChipWatchdog4 "Chip 4, shared by channels 9/10. SPIError includes MCU-detected SPI/frame/CRC errors.";
CM_ SG_ 160 FaultChipSPIError4 "Chip 4, shared by channels 9/10. SPIError includes MCU-detected SPI/frame/CRC errors.";
CM_ SG_ 160 FaultChipVBBUndervoltage4 "Chip 4, shared by channels 9/10. SPIError includes MCU-detected SPI/frame/CRC errors.";
CM_ SG_ 160 FaultChipWatchdog3 "Chip 3, shared by channels 7/8. SPIError includes MCU-detected SPI/frame/CRC errors.";
CM_ SG_ 160 FaultChipSPIError3 "Chip 3, shared by channels 7/8. SPIError includes MCU-detected SPI/frame/CRC errors.";
CM_ SG_ 160 FaultChipVBBUndervoltage3 "Chip 3, shared by channels 7/8. SPIError includes MCU-detected SPI/frame/CRC errors.";
CM_ SG_ 160 FaultChipWatchdog2 "Chip 2, shared by channels 5/6. SPIError includes MCU-detected SPI/frame/CRC errors.";
CM_ SG_ 160 FaultChipSPIError2 "Chip 2, shared by channels 5/6. SPIError includes MCU-detected SPI/frame/CRC errors.";
CM_ SG_ 160 FaultChipVBBUndervoltage2 "Chip 2, shared by channels 5/6. SPIError includes MCU-detected SPI/frame/CRC errors.";
CM_ SG_ 160 FaultChipWatchdog1 "Chip 1, shared by channels 3/4. SPIError includes MCU-detected SPI/frame/CRC errors.";
CM_ SG_ 160 FaultChipSPIError1 "Chip 1, shared by channels 3/4. SPIError includes MCU-detected SPI/frame/CRC errors.";
CM_ SG_ 160 FaultChipVBBUndervoltage1 "Chip 1, shared by channels 3/4. SPIError includes MCU-detected SPI/frame/CRC errors.";
CM_ SG_ 160 FaultChipWatchdog0 "Chip 0, shared by channels 1/2. SPIError includes MCU-detected SPI/frame/CRC errors.";
CM_ SG_ 160 FaultChipSPIError0 "Chip 0, shared by channels 1/2. SPIError includes MCU-detected SPI/frame/CRC errors.";
CM_ SG_ 160 FaultChipVBBUndervoltage0 "Chip 0, shared by channels 1/2. SPIError includes MCU-detected SPI/frame/CRC errors.";
CM_ SG_ 160 FaultChannelShortToBattery11 "Channel 11, HSS chip 5, output 2: ShortToBattery. OverTemperature combines absolute and relative thermal shutdown.";
CM_ SG_ 160 FaultChannelOpenLoad11 "Channel 11, HSS chip 5, output 2: OpenLoad. OverTemperature combines absolute and relative thermal shutdown.";
CM_ SG_ 160 FaultChannelOverTemperature11 "Channel 11, HSS chip 5, output 2: OverTemperature. OverTemperature combines absolute and relative thermal shutdown.";
CM_ SG_ 160 FaultChannelI2T11 "Channel 11, HSS chip 5, output 2: I2T. OverTemperature combines absolute and relative thermal shutdown.";
CM_ SG_ 160 FaultChannelOverCurrent11 "Channel 11, HSS chip 5, output 2: OverCurrent. OverTemperature combines absolute and relative thermal shutdown.";
CM_ SG_ 160 FaultChannelShortToBattery10 "Channel 10, HSS chip 5, output 1: ShortToBattery. OverTemperature combines absolute and relative thermal shutdown.";
CM_ SG_ 160 FaultChannelOpenLoad10 "Channel 10, HSS chip 5, output 1: OpenLoad. OverTemperature combines absolute and relative thermal shutdown.";
CM_ SG_ 160 FaultChannelOverTemperature10 "Channel 10, HSS chip 5, output 1: OverTemperature. OverTemperature combines absolute and relative thermal shutdown.";
CM_ SG_ 160 FaultChannelI2T10 "Channel 10, HSS chip 5, output 1: I2T. OverTemperature combines absolute and relative thermal shutdown.";
CM_ SG_ 160 FaultChannelOverCurrent10 "Channel 10, HSS chip 5, output 1: OverCurrent. OverTemperature combines absolute and relative thermal shutdown.";
CM_ SG_ 160 FaultChannelShortToBattery9 "Channel 9, HSS chip 4, output 2: ShortToBattery. OverTemperature combines absolute and relative thermal shutdown.";
CM_ SG_ 160 FaultChannelOpenLoad9 "Channel 9, HSS chip 4, output 2: OpenLoad. OverTemperature combines absolute and relative thermal shutdown.";
CM_ SG_ 160 FaultChannelOverTemperature9 "Channel 9, HSS chip 4, output 2: OverTemperature. OverTemperature combines absolute and relative thermal shutdown.";
CM_ SG_ 160 FaultChannelI2T9 "Channel 9, HSS chip 4, output 2: I2T. OverTemperature combines absolute and relative thermal shutdown.";
CM_ SG_ 160 FaultChannelOverCurrent9 "Channel 9, HSS chip 4, output 2: OverCurrent. OverTemperature combines absolute and relative thermal shutdown.";
CM_ SG_ 160 FaultChannelShortToBattery8 "Channel 8, HSS chip 4, output 1: ShortToBattery. OverTemperature combines absolute and relative thermal shutdown.";
CM_ SG_ 160 FaultChannelOpenLoad8 "Channel 8, HSS chip 4, output 1: OpenLoad. OverTemperature combines absolute and relative thermal shutdown.";
CM_ SG_ 160 FaultChannelOverTemperature8 "Channel 8, HSS chip 4, output 1: OverTemperature. OverTemperature combines absolute and relative thermal shutdown.";
CM_ SG_ 160 FaultChannelI2T8 "Channel 8, HSS chip 4, output 1: I2T. OverTemperature combines absolute and relative thermal shutdown.";
CM_ SG_ 160 FaultChannelOverCurrent8 "Channel 8, HSS chip 4, output 1: OverCurrent. OverTemperature combines absolute and relative thermal shutdown.";
CM_ SG_ 160 FaultChannelShortToBattery7 "Channel 7, HSS chip 3, output 2: ShortToBattery. OverTemperature combines absolute and relative thermal shutdown.";
CM_ SG_ 160 FaultChannelOpenLoad7 "Channel 7, HSS chip 3, output 2: OpenLoad. OverTemperature combines absolute and relative thermal shutdown.";
CM_ SG_ 160 FaultChannelOverTemperature7 "Channel 7, HSS chip 3, output 2: OverTemperature. OverTemperature combines absolute and relative thermal shutdown.";
CM_ SG_ 160 FaultChannelI2T7 "Channel 7, HSS chip 3, output 2: I2T. OverTemperature combines absolute and relative thermal shutdown.";
CM_ SG_ 160 FaultChannelOverCurrent7 "Channel 7, HSS chip 3, output 2: OverCurrent. OverTemperature combines absolute and relative thermal shutdown.";
CM_ SG_ 160 FaultChannelShortToBattery6 "Channel 6, HSS chip 3, output 1: ShortToBattery. OverTemperature combines absolute and relative thermal shutdown.";
CM_ SG_ 160 FaultChannelOpenLoad6 "Channel 6, HSS chip 3, output 1: OpenLoad. OverTemperature combines absolute and relative thermal shutdown.";
CM_ SG_ 160 FaultChannelOverTemperature6 "Channel 6, HSS chip 3, output 1: OverTemperature. OverTemperature combines absolute and relative thermal shutdown.";
CM_ SG_ 160 FaultChannelI2T6 "Channel 6, HSS chip 3, output 1: I2T. OverTemperature combines absolute and relative thermal shutdown.";
CM_ SG_ 160 FaultChannelOverCurrent6 "Channel 6, HSS chip 3, output 1: OverCurrent. OverTemperature combines absolute and relative thermal shutdown.";
CM_ SG_ 160 FaultChannelShortToBattery5 "Channel 5, HSS chip 2, output 2: ShortToBattery. OverTemperature combines absolute and relative thermal shutdown.";
CM_ SG_ 160 FaultChannelOpenLoad5 "Channel 5, HSS chip 2, output 2: OpenLoad. OverTemperature combines absolute and relative thermal shutdown.";
CM_ SG_ 160 FaultChannelOverTemperature5 "Channel 5, HSS chip 2, output 2: OverTemperature. OverTemperature combines absolute and relative thermal shutdown.";
CM_ SG_ 160 FaultChannelI2T5 "Channel 5, HSS chip 2, output 2: I2T. OverTemperature combines absolute and relative thermal shutdown.";
CM_ SG_ 160 FaultChannelOverCurrent5 "Channel 5, HSS chip 2, output 2: OverCurrent. OverTemperature combines absolute and relative thermal shutdown.";
CM_ SG_ 160 FaultChannelShortToBattery4 "Channel 4, HSS chip 2, output 1: ShortToBattery. OverTemperature combines absolute and relative thermal shutdown.";
CM_ SG_ 160 FaultChannelOpenLoad4 "Channel 4, HSS chip 2, output 1: OpenLoad. OverTemperature combines absolute and relative thermal shutdown.";
CM_ SG_ 160 FaultChannelOverTemperature4 "Channel 4, HSS chip 2, output 1: OverTemperature. OverTemperature combines absolute and relative thermal shutdown.";
CM_ SG_ 160 FaultChannelI2T4 "Channel 4, HSS chip 2, output 1: I2T. OverTemperature combines absolute and relative thermal shutdown.";
CM_ SG_ 160 FaultChannelOverCurrent4 "Channel 4, HSS chip 2, output 1: OverCurrent. OverTemperature combines absolute and relative thermal shutdown.";
CM_ SG_ 160 FaultChannelShortToBattery3 "Channel 3, HSS chip 1, output 2: ShortToBattery. OverTemperature combines absolute and relative thermal shutdown.";
CM_ SG_ 160 FaultChannelOpenLoad3 "Channel 3, HSS chip 1, output 2: OpenLoad. OverTemperature combines absolute and relative thermal shutdown.";
CM_ SG_ 160 FaultChannelOverTemperature3 "Channel 3, HSS chip 1, output 2: OverTemperature. OverTemperature combines absolute and relative thermal shutdown.";
CM_ SG_ 160 FaultChannelI2T3 "Channel 3, HSS chip 1, output 2: I2T. OverTemperature combines absolute and relative thermal shutdown.";
CM_ SG_ 160 FaultChannelOverCurrent3 "Channel 3, HSS chip 1, output 2: OverCurrent. OverTemperature combines absolute and relative thermal shutdown.";
CM_ SG_ 160 FaultChannelShortToBattery2 "Channel 2, HSS chip 1, output 1: ShortToBattery. OverTemperature combines absolute and relative thermal shutdown.";
CM_ SG_ 160 FaultChannelOpenLoad2 "Channel 2, HSS chip 1, output 1: OpenLoad. OverTemperature combines absolute and relative thermal shutdown.";
CM_ SG_ 160 FaultChannelOverTemperature2 "Channel 2, HSS chip 1, output 1: OverTemperature. OverTemperature combines absolute and relative thermal shutdown.";
CM_ SG_ 160 FaultChannelI2T2 "Channel 2, HSS chip 1, output 1: I2T. OverTemperature combines absolute and relative thermal shutdown.";
CM_ SG_ 160 FaultChannelOverCurrent2 "Channel 2, HSS chip 1, output 1: OverCurrent. OverTemperature combines absolute and relative thermal shutdown.";
CM_ SG_ 160 FaultChannelShortToBattery1 "Channel 1, HSS chip 0, output 2: ShortToBattery. OverTemperature combines absolute and relative thermal shutdown.";
CM_ SG_ 160 FaultChannelOpenLoad1 "Channel 1, HSS chip 0, output 2: OpenLoad. OverTemperature combines absolute and relative thermal shutdown.";
CM_ SG_ 160 FaultChannelOverTemperature1 "Channel 1, HSS chip 0, output 2: OverTemperature. OverTemperature combines absolute and relative thermal shutdown.";
CM_ SG_ 160 FaultChannelI2T1 "Channel 1, HSS chip 0, output 2: I2T. OverTemperature combines absolute and relative thermal shutdown.";
CM_ SG_ 160 FaultChannelOverCurrent1 "Channel 1, HSS chip 0, output 2: OverCurrent. OverTemperature combines absolute and relative thermal shutdown.";
CM_ SG_ 160 FaultChannelShortToBattery0 "Channel 0, HSS chip 0, output 1: ShortToBattery. OverTemperature combines absolute and relative thermal shutdown.";
CM_ SG_ 160 FaultChannelOpenLoad0 "Channel 0, HSS chip 0, output 1: OpenLoad. OverTemperature combines absolute and relative thermal shutdown.";
CM_ SG_ 160 FaultChannelOverTemperature0 "Channel 0, HSS chip 0, output 1: OverTemperature. OverTemperature combines absolute and relative thermal shutdown.";
CM_ SG_ 160 FaultChannelI2T0 "Channel 0, HSS chip 0, output 1: I2T. OverTemperature combines absolute and relative thermal shutdown.";
CM_ SG_ 160 FaultChannelOverCurrent0 "Channel 0, HSS chip 0, output 1: OverCurrent. OverTemperature combines absolute and relative thermal shutdown.";
CM_ BO_ 161 "10 Hz channel and total current measurements. Independent input measurement can include board consumption; do not label a computed channel sum as TotalCurrent.";
CM_ SG_ 161 TotalCurrent "Independently measured PDU input/total current, not a calculated channel sum.";
CM_ SG_ 161 ChannelCurrent11 "Measured HSS output current for channel 11; See chip SPI/watchdog faults when interpreting this reading.";
CM_ SG_ 161 ChannelCurrent10 "Measured HSS output current for channel 10; See chip SPI/watchdog faults when interpreting this reading.";
CM_ SG_ 161 ChannelCurrent9 "Measured HSS output current for channel 9; See chip SPI/watchdog faults when interpreting this reading.";
CM_ SG_ 161 ChannelCurrent8 "Measured HSS output current for channel 8; See chip SPI/watchdog faults when interpreting this reading.";
CM_ SG_ 161 ChannelCurrent7 "Measured HSS output current for channel 7; See chip SPI/watchdog faults when interpreting this reading.";
CM_ SG_ 161 ChannelCurrent6 "Measured HSS output current for channel 6; See chip SPI/watchdog faults when interpreting this reading.";
CM_ SG_ 161 ChannelCurrent5 "Measured HSS output current for channel 5; See chip SPI/watchdog faults when interpreting this reading.";
CM_ SG_ 161 ChannelCurrent4 "Measured HSS output current for channel 4; See chip SPI/watchdog faults when interpreting this reading.";
CM_ SG_ 161 ChannelCurrent3 "Measured HSS output current for channel 3; See chip SPI/watchdog faults when interpreting this reading.";
CM_ SG_ 161 ChannelCurrent2 "Measured HSS output current for channel 2; See chip SPI/watchdog faults when interpreting this reading.";
CM_ SG_ 161 ChannelCurrent1 "Measured HSS output current for channel 1; See chip SPI/watchdog faults when interpreting this reading.";
CM_ SG_ 161 ChannelCurrent0 "Measured HSS output current for channel 0; See chip SPI/watchdog faults when interpreting this reading.";
CM_ BO_ 162 "2 Hz input and per-channel output voltages, including 0 V when disabled. No per-reading validity bits are transmitted.";
CM_ SG_ 162 ChannelVoltage11 "Measured ChannelVoltage12. HSS-derived readings can stop updating when ADC conversion is suspended; consult sample age and chip diagnostics.";
CM_ SG_ 162 ChannelVoltage10 "Measured ChannelVoltage11. HSS-derived readings can stop updating when ADC conversion is suspended; consult sample age and chip diagnostics.";
CM_ SG_ 162 ChannelVoltage9 "Measured ChannelVoltage10. HSS-derived readings can stop updating when ADC conversion is suspended; consult sample age and chip diagnostics.";
CM_ SG_ 162 ChannelVoltage8 "Measured ChannelVoltage9. HSS-derived readings can stop updating when ADC conversion is suspended; consult sample age and chip diagnostics.";
CM_ SG_ 162 ChannelVoltage7 "Measured ChannelVoltage8. HSS-derived readings can stop updating when ADC conversion is suspended; consult sample age and chip diagnostics.";
CM_ SG_ 162 ChannelVoltage6 "Measured ChannelVoltage7. HSS-derived readings can stop updating when ADC conversion is suspended; consult sample age and chip diagnostics.";
CM_ SG_ 162 ChannelVoltage5 "Measured ChannelVoltage6. HSS-derived readings can stop updating when ADC conversion is suspended; consult sample age and chip diagnostics.";
CM_ SG_ 162 ChannelVoltage4 "Measured ChannelVoltage5. HSS-derived readings can stop updating when ADC conversion is suspended; consult sample age and chip diagnostics.";
CM_ SG_ 162 ChannelVoltage3 "Measured ChannelVoltage4. HSS-derived readings can stop updating when ADC conversion is suspended; consult sample age and chip diagnostics.";
CM_ SG_ 162 ChannelVoltage2 "Measured ChannelVoltage3. HSS-derived readings can stop updating when ADC conversion is suspended; consult sample age and chip diagnostics.";
CM_ SG_ 162 ChannelVoltage1 "Measured ChannelVoltage2. HSS-derived readings can stop updating when ADC conversion is suspended; consult sample age and chip diagnostics.";
CM_ SG_ 162 ChannelVoltage0 "Measured ChannelVoltage1. HSS-derived readings can stop updating when ADC conversion is suspended; consult sample age and chip diagnostics.";
CM_ SG_ 162 InputVoltage "Measured InputVoltage. HSS-derived readings can stop updating when ADC conversion is suspended; consult sample age and chip diagnostics.";
CM_ BO_ 163 "1 Hz per-channel FET temperatures; conversions may pause in some I2T modes; consult sample age and chip diagnostics.";
CM_ SG_ 163 ChannelTemperature11 "Channel 11 internal power-FET temperature, not load temperature.";
CM_ SG_ 163 ChannelTemperature10 "Channel 10 internal power-FET temperature, not load temperature.";
CM_ SG_ 163 ChannelTemperature9 "Channel 9 internal power-FET temperature, not load temperature.";
CM_ SG_ 163 ChannelTemperature8 "Channel 8 internal power-FET temperature, not load temperature.";
CM_ SG_ 163 ChannelTemperature7 "Channel 7 internal power-FET temperature, not load temperature.";
CM_ SG_ 163 ChannelTemperature6 "Channel 6 internal power-FET temperature, not load temperature.";
CM_ SG_ 163 ChannelTemperature5 "Channel 5 internal power-FET temperature, not load temperature.";
CM_ SG_ 163 ChannelTemperature4 "Channel 4 internal power-FET temperature, not load temperature.";
CM_ SG_ 163 ChannelTemperature3 "Channel 3 internal power-FET temperature, not load temperature.";
CM_ SG_ 163 ChannelTemperature2 "Channel 2 internal power-FET temperature, not load temperature.";
CM_ SG_ 163 ChannelTemperature1 "Channel 1 internal power-FET temperature, not load temperature.";
CM_ SG_ 163 ChannelTemperature0 "Channel 0 internal power-FET temperature, not load temperature.";
CM_ BO_ 164 "First latched overcurrent or I2T trip for the selected output. Retain each channel record until explicit reset. Send a newly captured trip promptly, then cycle through latched channels, sending one record at each 1000 ms interval while any trip remains latched. CaptureTimeMs is board uptime at detection; CurrentSampleAgeMs is age of the sampled current at detection. A saturated trip current is a lower bound, not an instantaneous peak.";
CM_ SG_ 164 TripCurrent "Captured current; independent record per output; saturation marks a lower bound.";
CM_ SG_ 164 CurrentSampleAgeMs "Age of the saved current sample when this channel tripped; frozen, saturates at 65535 ms.";
CM_ SG_ 164 CaptureTimeMs "Board uptime at the first latched trip; wraps at 2^32 ms. Interpret only while a trip flag is set.";
CM_ SG_ 164 ChannelIndex "Zero-based channel index: 0 selects Channel0; 11 selects Channel11.";
CM_ SG_ 164 TripCurrentSaturated "1 if the captured current is clipped or the sensing path was saturated; the current is then a lower bound, not an exact peak.";
CM_ SG_ 164 FaultI2T "Latched I2T trip for selected channel.";
CM_ SG_ 164 FaultOverCurrent "Latched OverCurrent trip for selected channel.";
BA_DEF_ SG_  "ValueTable" STRING ;
BA_DEF_ BO_  "LayoutPending" INT 0 1;
BA_DEF_ BO_  "ProtocolSource" STRING ;
BA_DEF_  "BusType" STRING ;
BA_DEF_  "DBName" STRING ;
BA_DEF_ SG_  "SystemSignalLongSymbol" STRING ;
BA_DEF_ BO_  "VFrameFormat" ENUM  "StandardCAN","ExtendedCAN","reserved","J1939PG","reserved","reserved","reserved","reserved","reserved","reserved","reserved","reserved","reserved","reserved","StandardCAN_FD","ExtendedCAN_FD";
BA_DEF_ BO_  "CANFD_BRS" ENUM  "0","1";
BA_DEF_ BO_  "GenMsgSendType" ENUM  "Cyclic","Triggered","None";
BA_DEF_ BO_  "GenMsgCycleTime" INT 0 65535;
BA_DEF_  "Baudrate" INT 1 10000000;
BA_DEF_  "DataBaudrate" INT 1 10000000;
BA_DEF_ BO_  "GenMsgSendCondition" STRING ;
BA_DEF_DEF_  "ValueTable" "";
BA_DEF_DEF_  "LayoutPending" 0;
BA_DEF_DEF_  "ProtocolSource" "";
BA_DEF_DEF_  "BusType" "CAN";
BA_DEF_DEF_  "DBName" "";
BA_DEF_DEF_  "SystemSignalLongSymbol" "";
BA_DEF_DEF_  "VFrameFormat" "StandardCAN";
BA_DEF_DEF_  "CANFD_BRS" "0";
BA_DEF_DEF_  "GenMsgSendType" "Cyclic";
BA_DEF_DEF_  "GenMsgCycleTime" 0;
BA_DEF_DEF_  "GenMsgSendCondition" "";
BA_ "BusType" "CAN FD";
BA_ "DBName" "CarCAN";
BA_ "Baudrate" 1000000;
BA_ "DataBaudrate" 1000000;
BA_ "ProtocolSource" BO_ 81 "2027 allocation draft";
BA_ "VFrameFormat" BO_ 81 14;
BA_ "GenMsgSendType" BO_ 81 1;
BA_ "ValueTable" SG_ 81 CurrentOverride "EnableDisable";
BA_ "ValueTable" SG_ 81 MPPTChargeScheme "NormalAdvanced";
BA_ "ValueTable" SG_ 81 Mode "NormalAdvanced";
BA_ "ProtocolSource" BO_ 82 "2027 allocation draft";
BA_ "VFrameFormat" BO_ 82 14;
BA_ "GenMsgSendType" BO_ 82 1;
BA_ "ValueTable" SG_ 82 Enable "EnableDisable";
BA_ "ProtocolSource" BO_ 83 "2027 allocation draft";
BA_ "VFrameFormat" BO_ 83 14;
BA_ "GenMsgSendType" BO_ 83 1;
BA_ "ValueTable" SG_ 83 CommandSource "MotorCommandSource";
BA_ "ProtocolSource" BO_ 84 "2027 allocation draft";
BA_ "VFrameFormat" BO_ 84 14;
BA_ "GenMsgSendType" BO_ 84 1;
BA_ "ProtocolSource" BO_ 85 "2027 allocation draft";
BA_ "VFrameFormat" BO_ 85 14;
BA_ "GenMsgSendType" BO_ 85 1;
BA_ "ValueTable" SG_ 85 BalancingMode "BalancingMode";
BA_ "ProtocolSource" BO_ 96 "2027 allocation draft";
BA_ "VFrameFormat" BO_ 96 14;
BA_ "GenMsgCycleTime" BO_ 96 200;
BA_ "ValueTable" SG_ 96 BalancingActive "OnOff";
BA_ "ValueTable" SG_ 96 MotorPrechargeRelay "OnOff";
BA_ "ValueTable" SG_ 96 MainPrechargeRelay "OnOff";
BA_ "ValueTable" SG_ 96 HVNegativeContactor "OnOff";
BA_ "ValueTable" SG_ 96 MotorContactor "OnOff";
BA_ "ValueTable" SG_ 96 HVPositiveContactor "OnOff";
BA_ "ValueTable" SG_ 96 RegenSafe "Permission";
BA_ "ValueTable" SG_ 96 MPPTSetMode "TPEEControlMode";
BA_ "ValueTable" SG_ 96 ChargeSafe "Permission";
BA_ "ValueTable" SG_ 96 DischargeSafe "Permission";
BA_ "ValueTable" SG_ 96 WarningBPSFan "WarningState";
BA_ "ValueTable" SG_ 96 WarningBatteryFan2 "WarningState";
BA_ "ValueTable" SG_ 96 WarningBatteryFan1 "WarningState";
BA_ "ValueTable" SG_ 96 WarningDischargeOverTemperature "WarningState";
BA_ "ValueTable" SG_ 96 WarningChargeOverTemperature "WarningState";
BA_ "ValueTable" SG_ 96 WarningOverVoltage "WarningState";
BA_ "ValueTable" SG_ 96 WarningUnderVoltage "WarningState";
BA_ "ValueTable" SG_ 96 WarningSMBCommunication "WarningState";
BA_ "ValueTable" SG_ 96 FaultMotorPrechargeVoltage "FaultState";
BA_ "ValueTable" SG_ 96 FaultMainPrechargeVoltage "FaultState";
BA_ "ValueTable" SG_ 96 FaultMotorVoltage "FaultState";
BA_ "ValueTable" SG_ 96 FaultMainVoltage "FaultState";
BA_ "ValueTable" SG_ 96 FaultMotorPrechargeTimeout "FaultState";
BA_ "ValueTable" SG_ 96 FaultMainPrechargeTimeout "FaultState";
BA_ "ValueTable" SG_ 96 FaultChargerEstop "FaultState";
BA_ "ValueTable" SG_ 96 FaultBatteryEstop "FaultState";
BA_ "ValueTable" SG_ 96 FaultExternalEstop "FaultState";
BA_ "ValueTable" SG_ 96 FaultDriverEstop "FaultState";
BA_ "ValueTable" SG_ 96 FaultMotorPrechargeRelayMismatch "FaultState";
BA_ "ValueTable" SG_ 96 FaultMainPrechargeRelayMismatch "FaultState";
BA_ "ValueTable" SG_ 96 FaultHVNegativeContactorMismatch "FaultState";
BA_ "ValueTable" SG_ 96 FaultMotorContactorMismatch "FaultState";
BA_ "ValueTable" SG_ 96 FaultHVPositiveContactorMismatch "FaultState";
BA_ "ValueTable" SG_ 96 FaultDischargeOverCurrent "FaultState";
BA_ "ValueTable" SG_ 96 FaultChargeOverCurrent "FaultState";
BA_ "ValueTable" SG_ 96 FaultUnderVoltage "FaultState";
BA_ "ValueTable" SG_ 96 FaultOverVoltage "FaultState";
BA_ "ValueTable" SG_ 96 FaultOverTemperature "FaultState";
BA_ "ValueTable" SG_ 96 FaultSummary "BPSFaultSummary";
BA_ "ValueTable" SG_ 96 Status "DeviceStatus";
BA_ "ProtocolSource" BO_ 97 "2027 allocation draft";
BA_ "VFrameFormat" BO_ 97 14;
BA_ "GenMsgCycleTime" BO_ 97 100;
BA_ "ValueTable" SG_ 97 HandbrakePressureSwitch "OnOff";
BA_ "ValueTable" SG_ 97 FrontPressureSwitch "OnOff";
BA_ "ValueTable" SG_ 97 BrakeActive "OnOff";
BA_ "ValueTable" SG_ 97 WarningPressureSwitchMismatch "WarningState";
BA_ "ValueTable" SG_ 97 WarningRedundantAcceleratorDisco "WarningState";
BA_ "SystemSignalLongSymbol" SG_ 97 WarningRedundantAcceleratorDisco "WarningRedundantAcceleratorDisconnected";
BA_ "ValueTable" SG_ 97 WarningMainAcceleratorDisconnect "WarningState";
BA_ "SystemSignalLongSymbol" SG_ 97 WarningMainAcceleratorDisconnect "WarningMainAcceleratorDisconnected";
BA_ "ValueTable" SG_ 97 FaultNoAccelerator "FaultState";
BA_ "ValueTable" SG_ 97 Status "FaultState";
BA_ "ProtocolSource" BO_ 98 "2027 allocation draft";
BA_ "VFrameFormat" BO_ 98 14;
BA_ "GenMsgCycleTime" BO_ 98 100;
BA_ "ValueTable" SG_ 98 Headlights "OnOff";
BA_ "ValueTable" SG_ 98 PushToTalk "Pressed";
BA_ "ValueTable" SG_ 98 Horn "OnOff";
BA_ "ValueTable" SG_ 98 RegenActivate "OnOff";
BA_ "ValueTable" SG_ 98 RegenEnable "EnableDisable";
BA_ "ValueTable" SG_ 98 RightTurnSignal "OnOff";
BA_ "ValueTable" SG_ 98 LeftTurnSignal "OnOff";
BA_ "ValueTable" SG_ 98 Hazards "OnOff";
BA_ "ValueTable" SG_ 98 Gear "Gear";
BA_ "ValueTable" SG_ 98 IgnitionDrive "OnOff";
BA_ "ValueTable" SG_ 98 IgnitionCharge "OnOff";
BA_ "ValueTable" SG_ 98 IgnitionLV "OnOff";
BA_ "ProtocolSource" BO_ 99 "2027 allocation draft";
BA_ "VFrameFormat" BO_ 99 14;
BA_ "GenMsgCycleTime" BO_ 99 200;
BA_ "ValueTable" SG_ 99 MotorCommandSource "MotorCommandSource";
BA_ "ValueTable" SG_ 99 FSMGear "Gear";
BA_ "ValueTable" SG_ 99 FSMDriverRegenRequest "OnOff";
BA_ "ValueTable" SG_ 99 FSMDriverRegenEnable "EnableDisable";
BA_ "ValueTable" SG_ 99 FSMBPSRegenOK "Permission";
BA_ "ValueTable" SG_ 99 FSMBPSDriveOK "Permission";
BA_ "ValueTable" SG_ 99 FSMBrake "OnOff";
BA_ "ValueTable" SG_ 99 State "VCUState";
BA_ "ValueTable" SG_ 99 RegenEnabled "EnableDisable";
BA_ "ValueTable" SG_ 99 WarningMotorFan "WarningState";
BA_ "ValueTable" SG_ 99 WarningMotorControllerFan "WarningState";
BA_ "ValueTable" SG_ 99 WarningDirectionChangeLockout "WarningState";
BA_ "ValueTable" SG_ 99 WarningTipping "WarningState";
BA_ "ValueTable" SG_ 99 FaultPedalsWatchdog "FaultState";
BA_ "ValueTable" SG_ 99 FaultDriverInputWatchdog "FaultState";
BA_ "ValueTable" SG_ 99 FaultBPSWatchdog "FaultState";
BA_ "ValueTable" SG_ 99 FaultMotorControllerWatchdog "FaultState";
BA_ "ValueTable" SG_ 99 FaultPedals "FaultState";
BA_ "ValueTable" SG_ 99 FaultBPS "FaultState";
BA_ "ValueTable" SG_ 99 FaultMotor "FaultState";
BA_ "ValueTable" SG_ 99 Status "FaultState";
BA_ "ProtocolSource" BO_ 112 "2027 allocation draft";
BA_ "VFrameFormat" BO_ 112 14;
BA_ "GenMsgCycleTime" BO_ 112 50;
BA_ "ProtocolSource" BO_ 113 "2027 allocation draft";
BA_ "VFrameFormat" BO_ 113 14;
BA_ "GenMsgCycleTime" BO_ 113 100;
BA_ "ProtocolSource" BO_ 114 "2027 allocation draft";
BA_ "VFrameFormat" BO_ 114 14;
BA_ "GenMsgCycleTime" BO_ 114 200;
BA_ "LayoutPending" BO_ 115 1;
BA_ "ProtocolSource" BO_ 115 "2027 allocation draft";
BA_ "VFrameFormat" BO_ 115 14;
BA_ "GenMsgCycleTime" BO_ 115 500;
BA_ "ProtocolSource" BO_ 116 "2027 allocation draft";
BA_ "VFrameFormat" BO_ 116 14;
BA_ "GenMsgCycleTime" BO_ 116 1000;
BA_ "ValueTable" SG_ 116 CurrentOverride "EnableDisable";
BA_ "ValueTable" SG_ 116 MPPTChargeScheme "NormalAdvanced";
BA_ "ValueTable" SG_ 116 Mode "NormalAdvanced";
BA_ "ProtocolSource" BO_ 117 "2027 allocation draft";
BA_ "VFrameFormat" BO_ 117 14;
BA_ "GenMsgSendType" BO_ 117 1;
BA_ "GenMsgCycleTime" BO_ 117 1000;
BA_ "GenMsgSendCondition" BO_ 117 "AnyBPSFaultActive && FaultSnapshotValid";
BA_ "ValueTable" SG_ 117 CurrentValid "Validity";
BA_ "ValueTable" SG_ 117 FaultMotorPrechargeVoltage "FaultState";
BA_ "ValueTable" SG_ 117 FaultMainPrechargeVoltage "FaultState";
BA_ "ValueTable" SG_ 117 FaultMotorVoltage "FaultState";
BA_ "ValueTable" SG_ 117 FaultMainVoltage "FaultState";
BA_ "ValueTable" SG_ 117 FaultMotorPrechargeTimeout "FaultState";
BA_ "ValueTable" SG_ 117 FaultMainPrechargeTimeout "FaultState";
BA_ "ValueTable" SG_ 117 FaultChargerEstop "FaultState";
BA_ "ValueTable" SG_ 117 FaultBatteryEstop "FaultState";
BA_ "ValueTable" SG_ 117 FaultExternalEstop "FaultState";
BA_ "ValueTable" SG_ 117 FaultDriverEstop "FaultState";
BA_ "ValueTable" SG_ 117 FaultMotorPrechargeRelayMismatch "FaultState";
BA_ "ValueTable" SG_ 117 FaultMainPrechargeRelayMismatch "FaultState";
BA_ "ValueTable" SG_ 117 FaultHVNegativeContactorMismatch "FaultState";
BA_ "ValueTable" SG_ 117 FaultMotorContactorMismatch "FaultState";
BA_ "ValueTable" SG_ 117 FaultHVPositiveContactorMismatch "FaultState";
BA_ "ValueTable" SG_ 117 FaultDischargeOverCurrent "FaultState";
BA_ "ValueTable" SG_ 117 FaultChargeOverCurrent "FaultState";
BA_ "ValueTable" SG_ 117 FaultUnderVoltage "FaultState";
BA_ "ValueTable" SG_ 117 FaultOverVoltage "FaultState";
BA_ "ValueTable" SG_ 117 FaultOverTemperature "FaultState";
BA_ "ValueTable" SG_ 117 FaultSummary "BPSFaultSummary";
BA_ "ProtocolSource" BO_ 118 "2027 allocation draft";
BA_ "VFrameFormat" BO_ 118 14;
BA_ "GenMsgSendType" BO_ 118 1;
BA_ "GenMsgCycleTime" BO_ 118 1000;
BA_ "GenMsgSendCondition" BO_ 118 "AnyBPSFaultActive && FaultSnapshotValid";
BA_ "ProtocolSource" BO_ 119 "2027 allocation draft";
BA_ "VFrameFormat" BO_ 119 14;
BA_ "GenMsgSendType" BO_ 119 1;
BA_ "GenMsgCycleTime" BO_ 119 1000;
BA_ "GenMsgSendCondition" BO_ 119 "AnyBPSFaultActive && FaultSnapshotValid";
BA_ "ProtocolSource" BO_ 120 "2027 allocation draft";
BA_ "VFrameFormat" BO_ 120 14;
BA_ "GenMsgSendType" BO_ 120 1;
BA_ "GenMsgCycleTime" BO_ 120 1000;
BA_ "GenMsgSendCondition" BO_ 120 "BalancingActive";
BA_ "ValueTable" SG_ 120 BlockReason "BalancingBlockReason";
BA_ "ValueTable" SG_ 120 BalancingState "BalancingState";
BA_ "ProtocolSource" BO_ 121 "2027 allocation draft";
BA_ "VFrameFormat" BO_ 121 14;
BA_ "GenMsgCycleTime" BO_ 121 500;
BA_ "ValueTable" SG_ 121 SweepingActive "OnOff";
BA_ "ValueTable" SG_ 121 MPPTSetMode "TPEEControlMode";
BA_ "ValueTable" SG_ 121 WarningFan "WarningState";
BA_ "ValueTable" SG_ 121 WarningMPPTCWatchdog "WarningState";
BA_ "ValueTable" SG_ 121 WarningMPPTBWatchdog "WarningState";
BA_ "ValueTable" SG_ 121 WarningMPPTAWatchdog "WarningState";
BA_ "ValueTable" SG_ 121 WarningBPSWatchdog "WarningState";
BA_ "ProtocolSource" BO_ 130 "2027 allocation draft";
BA_ "VFrameFormat" BO_ 130 14;
BA_ "GenMsgCycleTime" BO_ 130 500;
BA_ "ValueTable" SG_ 130 DriverCameraConnected "Connection";
BA_ "ValueTable" SG_ 130 GPSConnected "Connection";
BA_ "ValueTable" SG_ 130 ServerConnected "ServerConnection";
BA_ "ValueTable" SG_ 130 InternetConnected "Connection";
BA_ "ValueTable" SG_ 130 CellularConnected "Connection";
BA_ "ValueTable" SG_ 130 WarningRouterDisconnected "WarningState";
BA_ "ValueTable" SG_ 130 WarningRearCameraDisconnected "WarningState";
BA_ "ValueTable" SG_ 130 WarningDisplayDisconnected "WarningState";
BA_ "ValueTable" SG_ 130 WarningOverTemperature "WarningState";
BA_ "ValueTable" SG_ 130 WarningTemperature "WarningState";
BA_ "ProtocolSource" BO_ 144 "2027 allocation draft";
BA_ "VFrameFormat" BO_ 144 14;
BA_ "GenMsgCycleTime" BO_ 144 100;
BA_ "ValueTable" SG_ 144 BPSLVEnabled "EnableDisable";
BA_ "ValueTable" SG_ 144 DCDCEnabled "EnableDisable";
BA_ "ValueTable" SG_ 144 WarningBPSLVBlownFuse "WarningState";
BA_ "ValueTable" SG_ 144 WarningNoDCDCOutput "WarningState";
BA_ "ValueTable" SG_ 144 WarningHSSWatchdog "WarningState";
BA_ "ValueTable" SG_ 144 WarningHSSSPIError "WarningState";
BA_ "ValueTable" SG_ 144 WarningHSSVBBUndervoltage "WarningState";
BA_ "ValueTable" SG_ 144 WarningHSSShortToBattery "WarningState";
BA_ "ValueTable" SG_ 144 WarningHSSOpenLoad "WarningState";
BA_ "ValueTable" SG_ 144 WarningHSSOverTemperature "WarningState";
BA_ "ValueTable" SG_ 144 WarningHSSI2T "WarningState";
BA_ "ValueTable" SG_ 144 WarningHSSOverCurrent "WarningState";
BA_ "ProtocolSource" BO_ 145 "2027 allocation draft";
BA_ "VFrameFormat" BO_ 145 14;
BA_ "GenMsgCycleTime" BO_ 145 100;
BA_ "ProtocolSource" BO_ 146 "2027 allocation draft";
BA_ "VFrameFormat" BO_ 146 14;
BA_ "GenMsgCycleTime" BO_ 146 500;
BA_ "ProtocolSource" BO_ 147 "2027 allocation draft";
BA_ "VFrameFormat" BO_ 147 14;
BA_ "GenMsgCycleTime" BO_ 147 1000;
BA_ "ProtocolSource" BO_ 148 "2027 allocation draft";
BA_ "VFrameFormat" BO_ 148 14;
BA_ "GenMsgSendType" BO_ 148 1;
BA_ "GenMsgCycleTime" BO_ 148 1000;
BA_ "GenMsgSendCondition" BO_ 148 "AnyBPSOverCurrentOrI2TTripLatched";
BA_ "ValueTable" SG_ 148 TripCurrentSaturated "OnOff";
BA_ "ValueTable" SG_ 148 FaultI2T "FaultState";
BA_ "ValueTable" SG_ 148 FaultOverCurrent "FaultState";
BA_ "ProtocolSource" BO_ 160 "2027 allocation draft";
BA_ "VFrameFormat" BO_ 160 14;
BA_ "GenMsgCycleTime" BO_ 160 100;
BA_ "ValueTable" SG_ 160 ChannelEnabled11 "EnableDisable";
BA_ "ValueTable" SG_ 160 ChannelEnabled10 "EnableDisable";
BA_ "ValueTable" SG_ 160 ChannelEnabled9 "EnableDisable";
BA_ "ValueTable" SG_ 160 ChannelEnabled8 "EnableDisable";
BA_ "ValueTable" SG_ 160 ChannelEnabled7 "EnableDisable";
BA_ "ValueTable" SG_ 160 ChannelEnabled6 "EnableDisable";
BA_ "ValueTable" SG_ 160 ChannelEnabled5 "EnableDisable";
BA_ "ValueTable" SG_ 160 ChannelEnabled4 "EnableDisable";
BA_ "ValueTable" SG_ 160 ChannelEnabled3 "EnableDisable";
BA_ "ValueTable" SG_ 160 ChannelEnabled2 "EnableDisable";
BA_ "ValueTable" SG_ 160 ChannelEnabled1 "EnableDisable";
BA_ "ValueTable" SG_ 160 ChannelEnabled0 "EnableDisable";
BA_ "ValueTable" SG_ 160 WarningChannelBlownFuse11 "WarningState";
BA_ "ValueTable" SG_ 160 WarningChannelBlownFuse10 "WarningState";
BA_ "ValueTable" SG_ 160 WarningChannelBlownFuse9 "WarningState";
BA_ "ValueTable" SG_ 160 WarningChannelBlownFuse8 "WarningState";
BA_ "ValueTable" SG_ 160 WarningChannelBlownFuse7 "WarningState";
BA_ "ValueTable" SG_ 160 WarningChannelBlownFuse6 "WarningState";
BA_ "ValueTable" SG_ 160 WarningChannelBlownFuse5 "WarningState";
BA_ "ValueTable" SG_ 160 WarningChannelBlownFuse4 "WarningState";
BA_ "ValueTable" SG_ 160 WarningChannelBlownFuse3 "WarningState";
BA_ "ValueTable" SG_ 160 WarningChannelBlownFuse2 "WarningState";
BA_ "ValueTable" SG_ 160 WarningChannelBlownFuse1 "WarningState";
BA_ "ValueTable" SG_ 160 WarningChannelBlownFuse0 "WarningState";
BA_ "ValueTable" SG_ 160 WarningBlownFuse "WarningState";
BA_ "ValueTable" SG_ 160 FaultChipWatchdog5 "FaultState";
BA_ "ValueTable" SG_ 160 FaultChipSPIError5 "FaultState";
BA_ "ValueTable" SG_ 160 FaultChipVBBUndervoltage5 "FaultState";
BA_ "ValueTable" SG_ 160 FaultChipWatchdog4 "FaultState";
BA_ "ValueTable" SG_ 160 FaultChipSPIError4 "FaultState";
BA_ "ValueTable" SG_ 160 FaultChipVBBUndervoltage4 "FaultState";
BA_ "ValueTable" SG_ 160 FaultChipWatchdog3 "FaultState";
BA_ "ValueTable" SG_ 160 FaultChipSPIError3 "FaultState";
BA_ "ValueTable" SG_ 160 FaultChipVBBUndervoltage3 "FaultState";
BA_ "ValueTable" SG_ 160 FaultChipWatchdog2 "FaultState";
BA_ "ValueTable" SG_ 160 FaultChipSPIError2 "FaultState";
BA_ "ValueTable" SG_ 160 FaultChipVBBUndervoltage2 "FaultState";
BA_ "ValueTable" SG_ 160 FaultChipWatchdog1 "FaultState";
BA_ "ValueTable" SG_ 160 FaultChipSPIError1 "FaultState";
BA_ "ValueTable" SG_ 160 FaultChipVBBUndervoltage1 "FaultState";
BA_ "ValueTable" SG_ 160 FaultChipWatchdog0 "FaultState";
BA_ "ValueTable" SG_ 160 FaultChipSPIError0 "FaultState";
BA_ "ValueTable" SG_ 160 FaultChipVBBUndervoltage0 "FaultState";
BA_ "ValueTable" SG_ 160 FaultChannelShortToBattery11 "FaultState";
BA_ "ValueTable" SG_ 160 FaultChannelOpenLoad11 "FaultState";
BA_ "ValueTable" SG_ 160 FaultChannelOverTemperature11 "FaultState";
BA_ "ValueTable" SG_ 160 FaultChannelI2T11 "FaultState";
BA_ "ValueTable" SG_ 160 FaultChannelOverCurrent11 "FaultState";
BA_ "ValueTable" SG_ 160 FaultChannelShortToBattery10 "FaultState";
BA_ "ValueTable" SG_ 160 FaultChannelOpenLoad10 "FaultState";
BA_ "ValueTable" SG_ 160 FaultChannelOverTemperature10 "FaultState";
BA_ "ValueTable" SG_ 160 FaultChannelI2T10 "FaultState";
BA_ "ValueTable" SG_ 160 FaultChannelOverCurrent10 "FaultState";
BA_ "ValueTable" SG_ 160 FaultChannelShortToBattery9 "FaultState";
BA_ "ValueTable" SG_ 160 FaultChannelOpenLoad9 "FaultState";
BA_ "ValueTable" SG_ 160 FaultChannelOverTemperature9 "FaultState";
BA_ "ValueTable" SG_ 160 FaultChannelI2T9 "FaultState";
BA_ "ValueTable" SG_ 160 FaultChannelOverCurrent9 "FaultState";
BA_ "ValueTable" SG_ 160 FaultChannelShortToBattery8 "FaultState";
BA_ "ValueTable" SG_ 160 FaultChannelOpenLoad8 "FaultState";
BA_ "ValueTable" SG_ 160 FaultChannelOverTemperature8 "FaultState";
BA_ "ValueTable" SG_ 160 FaultChannelI2T8 "FaultState";
BA_ "ValueTable" SG_ 160 FaultChannelOverCurrent8 "FaultState";
BA_ "ValueTable" SG_ 160 FaultChannelShortToBattery7 "FaultState";
BA_ "ValueTable" SG_ 160 FaultChannelOpenLoad7 "FaultState";
BA_ "ValueTable" SG_ 160 FaultChannelOverTemperature7 "FaultState";
BA_ "ValueTable" SG_ 160 FaultChannelI2T7 "FaultState";
BA_ "ValueTable" SG_ 160 FaultChannelOverCurrent7 "FaultState";
BA_ "ValueTable" SG_ 160 FaultChannelShortToBattery6 "FaultState";
BA_ "ValueTable" SG_ 160 FaultChannelOpenLoad6 "FaultState";
BA_ "ValueTable" SG_ 160 FaultChannelOverTemperature6 "FaultState";
BA_ "ValueTable" SG_ 160 FaultChannelI2T6 "FaultState";
BA_ "ValueTable" SG_ 160 FaultChannelOverCurrent6 "FaultState";
BA_ "ValueTable" SG_ 160 FaultChannelShortToBattery5 "FaultState";
BA_ "ValueTable" SG_ 160 FaultChannelOpenLoad5 "FaultState";
BA_ "ValueTable" SG_ 160 FaultChannelOverTemperature5 "FaultState";
BA_ "ValueTable" SG_ 160 FaultChannelI2T5 "FaultState";
BA_ "ValueTable" SG_ 160 FaultChannelOverCurrent5 "FaultState";
BA_ "ValueTable" SG_ 160 FaultChannelShortToBattery4 "FaultState";
BA_ "ValueTable" SG_ 160 FaultChannelOpenLoad4 "FaultState";
BA_ "ValueTable" SG_ 160 FaultChannelOverTemperature4 "FaultState";
BA_ "ValueTable" SG_ 160 FaultChannelI2T4 "FaultState";
BA_ "ValueTable" SG_ 160 FaultChannelOverCurrent4 "FaultState";
BA_ "ValueTable" SG_ 160 FaultChannelShortToBattery3 "FaultState";
BA_ "ValueTable" SG_ 160 FaultChannelOpenLoad3 "FaultState";
BA_ "ValueTable" SG_ 160 FaultChannelOverTemperature3 "FaultState";
BA_ "ValueTable" SG_ 160 FaultChannelI2T3 "FaultState";
BA_ "ValueTable" SG_ 160 FaultChannelOverCurrent3 "FaultState";
BA_ "ValueTable" SG_ 160 FaultChannelShortToBattery2 "FaultState";
BA_ "ValueTable" SG_ 160 FaultChannelOpenLoad2 "FaultState";
BA_ "ValueTable" SG_ 160 FaultChannelOverTemperature2 "FaultState";
BA_ "ValueTable" SG_ 160 FaultChannelI2T2 "FaultState";
BA_ "ValueTable" SG_ 160 FaultChannelOverCurrent2 "FaultState";
BA_ "ValueTable" SG_ 160 FaultChannelShortToBattery1 "FaultState";
BA_ "ValueTable" SG_ 160 FaultChannelOpenLoad1 "FaultState";
BA_ "ValueTable" SG_ 160 FaultChannelOverTemperature1 "FaultState";
BA_ "ValueTable" SG_ 160 FaultChannelI2T1 "FaultState";
BA_ "ValueTable" SG_ 160 FaultChannelOverCurrent1 "FaultState";
BA_ "ValueTable" SG_ 160 FaultChannelShortToBattery0 "FaultState";
BA_ "ValueTable" SG_ 160 FaultChannelOpenLoad0 "FaultState";
BA_ "ValueTable" SG_ 160 FaultChannelOverTemperature0 "FaultState";
BA_ "ValueTable" SG_ 160 FaultChannelI2T0 "FaultState";
BA_ "ValueTable" SG_ 160 FaultChannelOverCurrent0 "FaultState";
BA_ "ProtocolSource" BO_ 161 "2027 allocation draft";
BA_ "VFrameFormat" BO_ 161 14;
BA_ "GenMsgCycleTime" BO_ 161 100;
BA_ "ProtocolSource" BO_ 162 "2027 allocation draft";
BA_ "VFrameFormat" BO_ 162 14;
BA_ "GenMsgCycleTime" BO_ 162 500;
BA_ "ProtocolSource" BO_ 163 "2027 allocation draft";
BA_ "VFrameFormat" BO_ 163 14;
BA_ "GenMsgCycleTime" BO_ 163 1000;
BA_ "ProtocolSource" BO_ 164 "2027 allocation draft";
BA_ "VFrameFormat" BO_ 164 14;
BA_ "GenMsgSendType" BO_ 164 1;
BA_ "GenMsgCycleTime" BO_ 164 1000;
BA_ "GenMsgSendCondition" BO_ 164 "AnyOverCurrentOrI2TTripLatched";
BA_ "ValueTable" SG_ 164 TripCurrentSaturated "OnOff";
BA_ "ValueTable" SG_ 164 FaultI2T "FaultState";
BA_ "ValueTable" SG_ 164 FaultOverCurrent "FaultState";
VAL_ 81 CurrentOverride 0 "Disabled" 1 "Enabled" ;
VAL_ 81 MPPTChargeScheme 0 "Normal" 1 "Advanced" ;
VAL_ 81 Mode 0 "Normal" 1 "Advanced" ;
VAL_ 82 Enable 0 "Disabled" 1 "Enabled" ;
VAL_ 83 CommandSource 0 "VCU" 1 "External" ;
VAL_ 85 BalancingMode 0 "Off" 1 "Automatic" 2 "Manual" ;
VAL_ 96 BalancingActive 0 "Off" 1 "On" ;
VAL_ 96 MotorPrechargeRelay 0 "Off" 1 "On" ;
VAL_ 96 MainPrechargeRelay 0 "Off" 1 "On" ;
VAL_ 96 HVNegativeContactor 0 "Off" 1 "On" ;
VAL_ 96 MotorContactor 0 "Off" 1 "On" ;
VAL_ 96 HVPositiveContactor 0 "Off" 1 "On" ;
VAL_ 96 RegenSafe 0 "NotAllowed" 1 "Allowed" ;
VAL_ 96 MPPTSetMode 0 "Disabled" 1 "PerturbAndObserve" 2 "ConstantInputVoltage" ;
VAL_ 96 ChargeSafe 0 "NotAllowed" 1 "Allowed" ;
VAL_ 96 DischargeSafe 0 "NotAllowed" 1 "Allowed" ;
VAL_ 96 WarningBPSFan 0 "NoWarning" 1 "Warning" ;
VAL_ 96 WarningBatteryFan2 0 "NoWarning" 1 "Warning" ;
VAL_ 96 WarningBatteryFan1 0 "NoWarning" 1 "Warning" ;
VAL_ 96 WarningDischargeOverTemperature 0 "NoWarning" 1 "Warning" ;
VAL_ 96 WarningChargeOverTemperature 0 "NoWarning" 1 "Warning" ;
VAL_ 96 WarningOverVoltage 0 "NoWarning" 1 "Warning" ;
VAL_ 96 WarningUnderVoltage 0 "NoWarning" 1 "Warning" ;
VAL_ 96 WarningSMBCommunication 0 "NoWarning" 1 "Warning" ;
VAL_ 96 FaultMotorPrechargeVoltage 0 "OK" 1 "Fault" ;
VAL_ 96 FaultMainPrechargeVoltage 0 "OK" 1 "Fault" ;
VAL_ 96 FaultMotorVoltage 0 "OK" 1 "Fault" ;
VAL_ 96 FaultMainVoltage 0 "OK" 1 "Fault" ;
VAL_ 96 FaultMotorPrechargeTimeout 0 "OK" 1 "Fault" ;
VAL_ 96 FaultMainPrechargeTimeout 0 "OK" 1 "Fault" ;
VAL_ 96 FaultChargerEstop 0 "OK" 1 "Fault" ;
VAL_ 96 FaultBatteryEstop 0 "OK" 1 "Fault" ;
VAL_ 96 FaultExternalEstop 0 "OK" 1 "Fault" ;
VAL_ 96 FaultDriverEstop 0 "OK" 1 "Fault" ;
VAL_ 96 FaultMotorPrechargeRelayMismatch 0 "OK" 1 "Fault" ;
VAL_ 96 FaultMainPrechargeRelayMismatch 0 "OK" 1 "Fault" ;
VAL_ 96 FaultHVNegativeContactorMismatch 0 "OK" 1 "Fault" ;
VAL_ 96 FaultMotorContactorMismatch 0 "OK" 1 "Fault" ;
VAL_ 96 FaultHVPositiveContactorMismatch 0 "OK" 1 "Fault" ;
VAL_ 96 FaultDischargeOverCurrent 0 "OK" 1 "Fault" ;
VAL_ 96 FaultChargeOverCurrent 0 "OK" 1 "Fault" ;
VAL_ 96 FaultUnderVoltage 0 "OK" 1 "Fault" ;
VAL_ 96 FaultOverVoltage 0 "OK" 1 "Fault" ;
VAL_ 96 FaultOverTemperature 0 "OK" 1 "Fault" ;
VAL_ 96 FaultSummary 0 "OK" 1 "SetpointFault" 2 "EmergencyStop" 3 "ContactorRelayFault" 4 "PrechargeFault" 5 "SMBFault" ;
VAL_ 96 Status 0 "OK" 1 "Fault" 2 "Waiting" ;
VAL_ 97 HandbrakePressureSwitch 0 "Off" 1 "On" ;
VAL_ 97 FrontPressureSwitch 0 "Off" 1 "On" ;
VAL_ 97 BrakeActive 0 "Off" 1 "On" ;
VAL_ 97 WarningPressureSwitchMismatch 0 "NoWarning" 1 "Warning" ;
VAL_ 97 WarningRedundantAcceleratorDisco 0 "NoWarning" 1 "Warning" ;
VAL_ 97 WarningMainAcceleratorDisconnect 0 "NoWarning" 1 "Warning" ;
VAL_ 97 FaultNoAccelerator 0 "OK" 1 "Fault" ;
VAL_ 97 Status 0 "OK" 1 "Fault" ;
VAL_ 98 Headlights 0 "Off" 1 "On" ;
VAL_ 98 PushToTalk 0 "NotPressed" 1 "Pressed" ;
VAL_ 98 Horn 0 "Off" 1 "On" ;
VAL_ 98 RegenActivate 0 "Off" 1 "On" ;
VAL_ 98 RegenEnable 0 "Disabled" 1 "Enabled" ;
VAL_ 98 RightTurnSignal 0 "Off" 1 "On" ;
VAL_ 98 LeftTurnSignal 0 "Off" 1 "On" ;
VAL_ 98 Hazards 0 "Off" 1 "On" ;
VAL_ 98 Gear 0 "Neutral" 1 "Forward" 2 "Reverse" 3 "Invalid" ;
VAL_ 98 IgnitionDrive 0 "Off" 1 "On" ;
VAL_ 98 IgnitionCharge 0 "Off" 1 "On" ;
VAL_ 98 IgnitionLV 0 "Off" 1 "On" ;
VAL_ 99 MotorCommandSource 0 "VCU" 1 "External" ;
VAL_ 99 FSMGear 0 "Neutral" 1 "Forward" 2 "Reverse" 3 "Invalid" ;
VAL_ 99 FSMDriverRegenRequest 0 "Off" 1 "On" ;
VAL_ 99 FSMDriverRegenEnable 0 "Disabled" 1 "Enabled" ;
VAL_ 99 FSMBPSRegenOK 0 "NotAllowed" 1 "Allowed" ;
VAL_ 99 FSMBPSDriveOK 0 "NotAllowed" 1 "Allowed" ;
VAL_ 99 FSMBrake 0 "Off" 1 "On" ;
VAL_ 99 State 0 "Init" 1 "ForwardDrive" 2 "NeutralDrive" 3 "ReverseDrive" 4 "Regen" 5 "CruiseControl" 6 "Disabled" 7 "VehicleNotReady" ;
VAL_ 99 RegenEnabled 0 "Disabled" 1 "Enabled" ;
VAL_ 99 WarningMotorFan 0 "NoWarning" 1 "Warning" ;
VAL_ 99 WarningMotorControllerFan 0 "NoWarning" 1 "Warning" ;
VAL_ 99 WarningDirectionChangeLockout 0 "NoWarning" 1 "Warning" ;
VAL_ 99 WarningTipping 0 "NoWarning" 1 "Warning" ;
VAL_ 99 FaultPedalsWatchdog 0 "OK" 1 "Fault" ;
VAL_ 99 FaultDriverInputWatchdog 0 "OK" 1 "Fault" ;
VAL_ 99 FaultBPSWatchdog 0 "OK" 1 "Fault" ;
VAL_ 99 FaultMotorControllerWatchdog 0 "OK" 1 "Fault" ;
VAL_ 99 FaultPedals 0 "OK" 1 "Fault" ;
VAL_ 99 FaultBPS 0 "OK" 1 "Fault" ;
VAL_ 99 FaultMotor 0 "OK" 1 "Fault" ;
VAL_ 99 Status 0 "OK" 1 "Fault" ;
VAL_ 116 CurrentOverride 0 "Disabled" 1 "Enabled" ;
VAL_ 116 MPPTChargeScheme 0 "Normal" 1 "Advanced" ;
VAL_ 116 Mode 0 "Normal" 1 "Advanced" ;
VAL_ 117 CurrentValid 1 "Valid" 0 "Invalid" ;
VAL_ 117 FaultMotorPrechargeVoltage 0 "OK" 1 "Fault" ;
VAL_ 117 FaultMainPrechargeVoltage 0 "OK" 1 "Fault" ;
VAL_ 117 FaultMotorVoltage 0 "OK" 1 "Fault" ;
VAL_ 117 FaultMainVoltage 0 "OK" 1 "Fault" ;
VAL_ 117 FaultMotorPrechargeTimeout 0 "OK" 1 "Fault" ;
VAL_ 117 FaultMainPrechargeTimeout 0 "OK" 1 "Fault" ;
VAL_ 117 FaultChargerEstop 0 "OK" 1 "Fault" ;
VAL_ 117 FaultBatteryEstop 0 "OK" 1 "Fault" ;
VAL_ 117 FaultExternalEstop 0 "OK" 1 "Fault" ;
VAL_ 117 FaultDriverEstop 0 "OK" 1 "Fault" ;
VAL_ 117 FaultMotorPrechargeRelayMismatch 0 "OK" 1 "Fault" ;
VAL_ 117 FaultMainPrechargeRelayMismatch 0 "OK" 1 "Fault" ;
VAL_ 117 FaultHVNegativeContactorMismatch 0 "OK" 1 "Fault" ;
VAL_ 117 FaultMotorContactorMismatch 0 "OK" 1 "Fault" ;
VAL_ 117 FaultHVPositiveContactorMismatch 0 "OK" 1 "Fault" ;
VAL_ 117 FaultDischargeOverCurrent 0 "OK" 1 "Fault" ;
VAL_ 117 FaultChargeOverCurrent 0 "OK" 1 "Fault" ;
VAL_ 117 FaultUnderVoltage 0 "OK" 1 "Fault" ;
VAL_ 117 FaultOverVoltage 0 "OK" 1 "Fault" ;
VAL_ 117 FaultOverTemperature 0 "OK" 1 "Fault" ;
VAL_ 117 FaultSummary 0 "OK" 1 "SetpointFault" 2 "EmergencyStop" 3 "ContactorRelayFault" 4 "PrechargeFault" 5 "SMBFault" ;
VAL_ 120 BlockReason 0 "None" 1 "CellTemperature" 2 "ChipTemperature" 3 "CellVoltage" 4 "VehicleState" 5 "Communication" 6 "BPSFault" 7 "Other" ;
VAL_ 120 BalancingState 0 "Off" 1 "Balancing" 2 "Paused" 3 "Complete" 4 "BlockedOrFault" ;
VAL_ 121 SweepingActive 0 "Off" 1 "On" ;
VAL_ 121 MPPTSetMode 0 "Disabled" 1 "PerturbAndObserve" 2 "ConstantInputVoltage" ;
VAL_ 121 WarningFan 0 "NoWarning" 1 "Warning" ;
VAL_ 121 WarningMPPTCWatchdog 0 "NoWarning" 1 "Warning" ;
VAL_ 121 WarningMPPTBWatchdog 0 "NoWarning" 1 "Warning" ;
VAL_ 121 WarningMPPTAWatchdog 0 "NoWarning" 1 "Warning" ;
VAL_ 121 WarningBPSWatchdog 0 "NoWarning" 1 "Warning" ;
VAL_ 130 DriverCameraConnected 0 "Disconnected" 1 "Connected" ;
VAL_ 130 GPSConnected 0 "Disconnected" 1 "Connected" ;
VAL_ 130 ServerConnected 0 "Disconnected/Retrying" 1 "Connected" ;
VAL_ 130 InternetConnected 0 "Disconnected" 1 "Connected" ;
VAL_ 130 CellularConnected 0 "Disconnected" 1 "Connected" ;
VAL_ 130 WarningRouterDisconnected 0 "NoWarning" 1 "Warning" ;
VAL_ 130 WarningRearCameraDisconnected 0 "NoWarning" 1 "Warning" ;
VAL_ 130 WarningDisplayDisconnected 0 "NoWarning" 1 "Warning" ;
VAL_ 130 WarningOverTemperature 0 "NoWarning" 1 "Warning" ;
VAL_ 130 WarningTemperature 0 "NoWarning" 1 "Warning" ;
VAL_ 144 BPSLVEnabled 1 "Enabled" 0 "Disabled" ;
VAL_ 144 DCDCEnabled 1 "Enabled" 0 "Disabled" ;
VAL_ 144 WarningBPSLVBlownFuse 1 "Warning" 0 "NoWarning" ;
VAL_ 144 WarningNoDCDCOutput 1 "Warning" 0 "NoWarning" ;
VAL_ 144 WarningHSSWatchdog 1 "Warning" 0 "NoWarning" ;
VAL_ 144 WarningHSSSPIError 1 "Warning" 0 "NoWarning" ;
VAL_ 144 WarningHSSVBBUndervoltage 1 "Warning" 0 "NoWarning" ;
VAL_ 144 WarningHSSShortToBattery 1 "Warning" 0 "NoWarning" ;
VAL_ 144 WarningHSSOpenLoad 1 "Warning" 0 "NoWarning" ;
VAL_ 144 WarningHSSOverTemperature 1 "Warning" 0 "NoWarning" ;
VAL_ 144 WarningHSSI2T 1 "Warning" 0 "NoWarning" ;
VAL_ 144 WarningHSSOverCurrent 1 "Warning" 0 "NoWarning" ;
VAL_ 148 TripCurrentSaturated 1 "On" 0 "Off" ;
VAL_ 148 FaultI2T 1 "Fault" 0 "OK" ;
VAL_ 148 FaultOverCurrent 1 "Fault" 0 "OK" ;
VAL_ 160 ChannelEnabled11 1 "Enabled" 0 "Disabled" ;
VAL_ 160 ChannelEnabled10 1 "Enabled" 0 "Disabled" ;
VAL_ 160 ChannelEnabled9 1 "Enabled" 0 "Disabled" ;
VAL_ 160 ChannelEnabled8 1 "Enabled" 0 "Disabled" ;
VAL_ 160 ChannelEnabled7 1 "Enabled" 0 "Disabled" ;
VAL_ 160 ChannelEnabled6 1 "Enabled" 0 "Disabled" ;
VAL_ 160 ChannelEnabled5 1 "Enabled" 0 "Disabled" ;
VAL_ 160 ChannelEnabled4 1 "Enabled" 0 "Disabled" ;
VAL_ 160 ChannelEnabled3 1 "Enabled" 0 "Disabled" ;
VAL_ 160 ChannelEnabled2 1 "Enabled" 0 "Disabled" ;
VAL_ 160 ChannelEnabled1 1 "Enabled" 0 "Disabled" ;
VAL_ 160 ChannelEnabled0 1 "Enabled" 0 "Disabled" ;
VAL_ 160 WarningChannelBlownFuse11 1 "Warning" 0 "NoWarning" ;
VAL_ 160 WarningChannelBlownFuse10 1 "Warning" 0 "NoWarning" ;
VAL_ 160 WarningChannelBlownFuse9 1 "Warning" 0 "NoWarning" ;
VAL_ 160 WarningChannelBlownFuse8 1 "Warning" 0 "NoWarning" ;
VAL_ 160 WarningChannelBlownFuse7 1 "Warning" 0 "NoWarning" ;
VAL_ 160 WarningChannelBlownFuse6 1 "Warning" 0 "NoWarning" ;
VAL_ 160 WarningChannelBlownFuse5 1 "Warning" 0 "NoWarning" ;
VAL_ 160 WarningChannelBlownFuse4 1 "Warning" 0 "NoWarning" ;
VAL_ 160 WarningChannelBlownFuse3 1 "Warning" 0 "NoWarning" ;
VAL_ 160 WarningChannelBlownFuse2 1 "Warning" 0 "NoWarning" ;
VAL_ 160 WarningChannelBlownFuse1 1 "Warning" 0 "NoWarning" ;
VAL_ 160 WarningChannelBlownFuse0 1 "Warning" 0 "NoWarning" ;
VAL_ 160 WarningBlownFuse 1 "Warning" 0 "NoWarning" ;
VAL_ 160 FaultChipWatchdog5 1 "Fault" 0 "OK" ;
VAL_ 160 FaultChipSPIError5 1 "Fault" 0 "OK" ;
VAL_ 160 FaultChipVBBUndervoltage5 1 "Fault" 0 "OK" ;
VAL_ 160 FaultChipWatchdog4 1 "Fault" 0 "OK" ;
VAL_ 160 FaultChipSPIError4 1 "Fault" 0 "OK" ;
VAL_ 160 FaultChipVBBUndervoltage4 1 "Fault" 0 "OK" ;
VAL_ 160 FaultChipWatchdog3 1 "Fault" 0 "OK" ;
VAL_ 160 FaultChipSPIError3 1 "Fault" 0 "OK" ;
VAL_ 160 FaultChipVBBUndervoltage3 1 "Fault" 0 "OK" ;
VAL_ 160 FaultChipWatchdog2 1 "Fault" 0 "OK" ;
VAL_ 160 FaultChipSPIError2 1 "Fault" 0 "OK" ;
VAL_ 160 FaultChipVBBUndervoltage2 1 "Fault" 0 "OK" ;
VAL_ 160 FaultChipWatchdog1 1 "Fault" 0 "OK" ;
VAL_ 160 FaultChipSPIError1 1 "Fault" 0 "OK" ;
VAL_ 160 FaultChipVBBUndervoltage1 1 "Fault" 0 "OK" ;
VAL_ 160 FaultChipWatchdog0 1 "Fault" 0 "OK" ;
VAL_ 160 FaultChipSPIError0 1 "Fault" 0 "OK" ;
VAL_ 160 FaultChipVBBUndervoltage0 1 "Fault" 0 "OK" ;
VAL_ 160 FaultChannelShortToBattery11 1 "Fault" 0 "OK" ;
VAL_ 160 FaultChannelOpenLoad11 1 "Fault" 0 "OK" ;
VAL_ 160 FaultChannelOverTemperature11 1 "Fault" 0 "OK" ;
VAL_ 160 FaultChannelI2T11 1 "Fault" 0 "OK" ;
VAL_ 160 FaultChannelOverCurrent11 1 "Fault" 0 "OK" ;
VAL_ 160 FaultChannelShortToBattery10 1 "Fault" 0 "OK" ;
VAL_ 160 FaultChannelOpenLoad10 1 "Fault" 0 "OK" ;
VAL_ 160 FaultChannelOverTemperature10 1 "Fault" 0 "OK" ;
VAL_ 160 FaultChannelI2T10 1 "Fault" 0 "OK" ;
VAL_ 160 FaultChannelOverCurrent10 1 "Fault" 0 "OK" ;
VAL_ 160 FaultChannelShortToBattery9 1 "Fault" 0 "OK" ;
VAL_ 160 FaultChannelOpenLoad9 1 "Fault" 0 "OK" ;
VAL_ 160 FaultChannelOverTemperature9 1 "Fault" 0 "OK" ;
VAL_ 160 FaultChannelI2T9 1 "Fault" 0 "OK" ;
VAL_ 160 FaultChannelOverCurrent9 1 "Fault" 0 "OK" ;
VAL_ 160 FaultChannelShortToBattery8 1 "Fault" 0 "OK" ;
VAL_ 160 FaultChannelOpenLoad8 1 "Fault" 0 "OK" ;
VAL_ 160 FaultChannelOverTemperature8 1 "Fault" 0 "OK" ;
VAL_ 160 FaultChannelI2T8 1 "Fault" 0 "OK" ;
VAL_ 160 FaultChannelOverCurrent8 1 "Fault" 0 "OK" ;
VAL_ 160 FaultChannelShortToBattery7 1 "Fault" 0 "OK" ;
VAL_ 160 FaultChannelOpenLoad7 1 "Fault" 0 "OK" ;
VAL_ 160 FaultChannelOverTemperature7 1 "Fault" 0 "OK" ;
VAL_ 160 FaultChannelI2T7 1 "Fault" 0 "OK" ;
VAL_ 160 FaultChannelOverCurrent7 1 "Fault" 0 "OK" ;
VAL_ 160 FaultChannelShortToBattery6 1 "Fault" 0 "OK" ;
VAL_ 160 FaultChannelOpenLoad6 1 "Fault" 0 "OK" ;
VAL_ 160 FaultChannelOverTemperature6 1 "Fault" 0 "OK" ;
VAL_ 160 FaultChannelI2T6 1 "Fault" 0 "OK" ;
VAL_ 160 FaultChannelOverCurrent6 1 "Fault" 0 "OK" ;
VAL_ 160 FaultChannelShortToBattery5 1 "Fault" 0 "OK" ;
VAL_ 160 FaultChannelOpenLoad5 1 "Fault" 0 "OK" ;
VAL_ 160 FaultChannelOverTemperature5 1 "Fault" 0 "OK" ;
VAL_ 160 FaultChannelI2T5 1 "Fault" 0 "OK" ;
VAL_ 160 FaultChannelOverCurrent5 1 "Fault" 0 "OK" ;
VAL_ 160 FaultChannelShortToBattery4 1 "Fault" 0 "OK" ;
VAL_ 160 FaultChannelOpenLoad4 1 "Fault" 0 "OK" ;
VAL_ 160 FaultChannelOverTemperature4 1 "Fault" 0 "OK" ;
VAL_ 160 FaultChannelI2T4 1 "Fault" 0 "OK" ;
VAL_ 160 FaultChannelOverCurrent4 1 "Fault" 0 "OK" ;
VAL_ 160 FaultChannelShortToBattery3 1 "Fault" 0 "OK" ;
VAL_ 160 FaultChannelOpenLoad3 1 "Fault" 0 "OK" ;
VAL_ 160 FaultChannelOverTemperature3 1 "Fault" 0 "OK" ;
VAL_ 160 FaultChannelI2T3 1 "Fault" 0 "OK" ;
VAL_ 160 FaultChannelOverCurrent3 1 "Fault" 0 "OK" ;
VAL_ 160 FaultChannelShortToBattery2 1 "Fault" 0 "OK" ;
VAL_ 160 FaultChannelOpenLoad2 1 "Fault" 0 "OK" ;
VAL_ 160 FaultChannelOverTemperature2 1 "Fault" 0 "OK" ;
VAL_ 160 FaultChannelI2T2 1 "Fault" 0 "OK" ;
VAL_ 160 FaultChannelOverCurrent2 1 "Fault" 0 "OK" ;
VAL_ 160 FaultChannelShortToBattery1 1 "Fault" 0 "OK" ;
VAL_ 160 FaultChannelOpenLoad1 1 "Fault" 0 "OK" ;
VAL_ 160 FaultChannelOverTemperature1 1 "Fault" 0 "OK" ;
VAL_ 160 FaultChannelI2T1 1 "Fault" 0 "OK" ;
VAL_ 160 FaultChannelOverCurrent1 1 "Fault" 0 "OK" ;
VAL_ 160 FaultChannelShortToBattery0 1 "Fault" 0 "OK" ;
VAL_ 160 FaultChannelOpenLoad0 1 "Fault" 0 "OK" ;
VAL_ 160 FaultChannelOverTemperature0 1 "Fault" 0 "OK" ;
VAL_ 160 FaultChannelI2T0 1 "Fault" 0 "OK" ;
VAL_ 160 FaultChannelOverCurrent0 1 "Fault" 0 "OK" ;
VAL_ 164 TripCurrentSaturated 1 "On" 0 "Off" ;
VAL_ 164 FaultI2T 1 "Fault" 0 "OK" ;
VAL_ 164 FaultOverCurrent 1 "Fault" 0 "OK" ;
